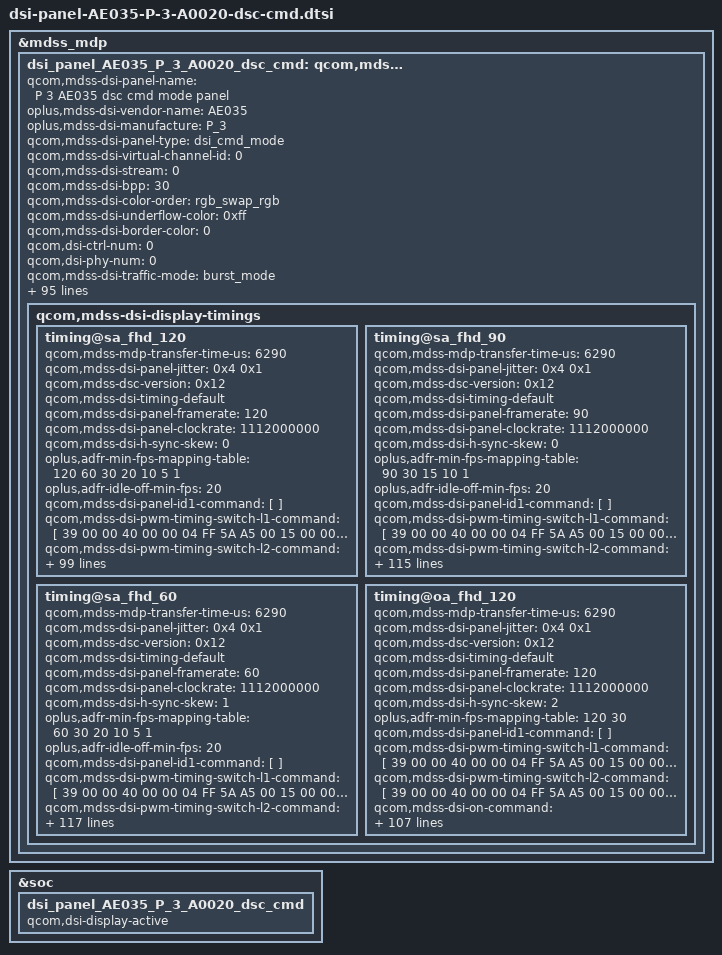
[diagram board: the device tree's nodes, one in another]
&mdss_mdp {
	dsi_panel_AE035_P_3_A0020_dsc_cmd: qcom,mdss_dsi_panel_AE035_P_3_A0020_dsc_cmd {
		qcom,mdss-dsi-panel-name = "P 3 AE035 dsc cmd mode panel";
		oplus,mdss-dsi-vendor-name = "AE035";
		oplus,mdss-dsi-manufacture = "P_3";
		qcom,mdss-dsi-panel-type = "dsi_cmd_mode";
		qcom,mdss-dsi-virtual-channel-id = <0>;
		qcom,mdss-dsi-stream = <0>;
		qcom,mdss-dsi-bpp = <30>;
		qcom,mdss-dsi-color-order = "rgb_swap_rgb";
		qcom,mdss-dsi-underflow-color = <0xff>;
		qcom,mdss-dsi-border-color = <0>;
		qcom,dsi-ctrl-num = <0>;
		qcom,dsi-phy-num = <0>;
		qcom,mdss-dsi-traffic-mode = "burst_mode";
		qcom,mdss-dsi-lane-map = "lane_map_0123";
		qcom,mdss-dsi-bllp-eof-power-mode;
		qcom,mdss-dsi-bllp-power-mode;
		qcom,mdss-dsi-lane-0-state;
		qcom,mdss-dsi-lane-1-state;
		qcom,mdss-dsi-lane-2-state;
		qcom,mdss-dsi-lane-3-state;
		qcom,mdss-dsi-dma-trigger = "trigger_sw";
		qcom,mdss-dsi-dma-schedule-line = <1>;
		qcom,mdss-dsi-dma-schedule-window = <10>;
		qcom,mdss-dsi-mdp-trigger = "none";
		qcom,mdss-dsi-reset-sequence = <1 2>, <0 5>, <1 25>;
		qcom,mdss-dsi-te-pin-select = <1>;
		qcom,mdss-dsi-te-dcs-command = <1>;
		qcom,mdss-pan-physical-width-dimension = <71>;
		qcom,mdss-pan-physical-height-dimension = <157>;
		qcom,mdss-dsi-init-delay-us = <1000>;
		qcom,mdss-dsi-te-check-enable;
		qcom,mdss-dsi-te-using-te-pin;
		//qcom,mdss-dsi-lp11-init;
		qcom,mdss-dsi-wr-mem-start = <0x2c>;
		qcom,mdss-dsi-wr-mem-continue = <0x3c>;
		qcom,mdss-dsi-panel-jitter = <0x4 0x1>;
		qcom,mdss-bl-high2bit;
		/* HDR Setting */
		qcom,mdss-dsi-panel-hdr-enabled;
		qcom,mdss-dsi-panel-hdr-color-primaries = <15635 16450 34000 16000 13250 34500 7500 3000>;
		qcom,mdss-dsi-panel-peak-brightness = <5400000>;
		qcom,mdss-dsi-panel-average-brightness = <2000000>;
		qcom,mdss-dsi-panel-blackness-level = <4000>;

		qcom,esd-check-enabled;
		oplus,esd-check-flag-enabled;
		qcom,mdss-dsi-panel-status-check-mode = "reg_read";
		qcom,mdss-dsi-panel-status-command = [
				06 00 00 00 00 00 01 0A
			];
		qcom,mdss-dsi-panel-status-command-state = "dsi_lp_mode";
		qcom,mdss-dsi-panel-status-value = <0x9C>;
		qcom,mdss-dsi-panel-status-read-length = <1>;

		qcom,mdss-dsi-display-timings {
			timing@sa_fhd_120 {
				#include "dsi-panel-AE035-P-3-A0020-dsc-cmd-common.dtsi"
				qcom,mdss-mdp-transfer-time-us = <6290>;
				qcom,mdss-dsi-panel-jitter = <0x4 0x1>;
				qcom,mdss-dsc-version = <0x12>;
				qcom,mdss-dsi-timing-default;
				qcom,mdss-dsi-panel-framerate = <120>;
				qcom,mdss-dsi-panel-clockrate = <1112000000>;

				/* standard adfr */
				qcom,mdss-dsi-h-sync-skew = <0>;
				oplus,adfr-min-fps-mapping-table = <120 60 30 20 10 5 1>;
				oplus,adfr-idle-off-min-fps = <20>;

				// oplus,ofp-need-to-sync-data-in-aod-unlocking;
				// oplus,ofp-aod-off-insert-black-frame = <1>;
				// oplus,ofp-aod-off-black-frame-total-time = <42>;
				// oplus,ofp-need-to-separate-backlight;
				// oplus,ofp-backlight-on-period = <1>;

				qcom,mdss-dsi-panel-id1-command = [

				];

				qcom,mdss-dsi-pwm-timing-switch-l1-command = [
						39 00 00 40 00 00 04 FF 5A A5 00
						15 00 00 40 00 00 02 60 00
						39 00 00 40 00 00 04 FF 5A A5 2D
						39 00 00 40 00 00 03 83 00 00
						15 00 00 40 00 00 02 F2 00
						39 00 00 00 00 00 04 FF 5A A5 00
				];

				qcom,mdss-dsi-pwm-timing-switch-l2-command = [
                                                39 00 00 40 00 00 04 FF 5A A5 00
                                                15 00 00 40 00 00 02 60 01
                                                39 00 00 40 00 00 04 FF 5A A5 2D
                                                39 00 00 40 00 00 03 84 00 00
                                                15 00 00 40 00 00 02 F2 00
                                                39 00 00 00 00 00 04 FF 5A A5 00
                                ];

				qcom,mdss-dsi-on-command = [
						39 00 00 40 00 00 04 FF 5A A5 08
						15 00 00 40 00 00 02 C8 62 // Sleep out don't reload
							/* PPS setting */
						39 00 00 40 00 00 04 FF 5A A5 07
						15 00 00 40 00 00 02 8A 01 // PPS Enable
						39 00 00 40 00 00 03 8B 11 E0 // PPS Table
						39 00 00 40 00 00 64 81 00 00 00 00 00 12 00
											00 AB 30 80 0A DC 04 F0
											00 14 02 78 02 78 02 00
											02 57 00 20 01 F8 00 08
											00 0D 05 7A 04 4F 18 00
											10 E0 07 10 20 00 06 0F
											0F 33 0E 1C 2A 38 46 54
											62 69 70 77 79 7B 7D 7E
											02 02 22 00 2A 40 2A BE
											3A FC 3A FA 3A F8 3B 38
											3B 78 3B B6 4B B6 4B F4
											4B F4 6C 34 84 74 00 00
											00 00 00 00
						39 00 00 40 00 00 04 FF 5A A5 21
						15 00 00 40 00 00 02 A4 18 // Flash reload enable
						/* ODC Compensation */
						39 00 00 40 00 00 04 FF 5A A5 49
						39 00 00 40 00 00 11 81 10 00 F3 01 3B 02 45 02 45 02 A9 03 8D 05 DD 06
						15 00 00 40 00 00 02 E0 01
						39 00 00 40 00 00 04 FF 5A A5 5A
						39 00 00 40 00 00 04 80 00 00 00
						39 00 00 40 00 00 04 81 19 25 1B
						39 00 00 40 00 00 04 82 10 20 14
						39 00 00 40 00 00 04 83 03 12 03
						39 00 00 40 00 00 04 84 01 0A 04
						39 00 00 40 00 00 04 85 01 0A 00
						39 00 00 40 00 00 04 86 02 22 12
						39 00 00 40 00 00 04 87 02 1C 0A
						39 00 00 40 00 00 04 88 02 16 08
						39 00 00 40 00 00 04 89 00 0A 08
						39 00 00 40 00 00 04 8A 01 24 20
						39 00 00 40 00 00 04 8B 01 1D 11
						39 00 00 40 00 00 04 8C 00 15 10
						39 00 00 40 00 00 04 8D 00 0E 0C
						39 00 00 40 00 00 04 8E 00 07 09
						39 00 00 40 00 00 04 8F 00 25 28
						39 00 00 40 00 00 04 90 02 1C 16
						39 00 00 40 00 00 04 91 02 12 14
						39 00 00 40 00 00 04 92 01 08 12
						39 00 00 40 00 00 04 93 01 06 0F
						39 00 00 40 00 00 04 94 00 03 02
						39 00 00 40 00 00 04 95 02 28 26
						39 00 00 40 00 00 04 96 02 22 24
						39 00 00 40 00 00 04 97 03 15 1E
						39 00 00 40 00 00 04 98 01 12 18
						39 00 00 40 00 00 04 99 01 07 16
						39 00 00 40 00 00 04 9A 01 05 0A
						39 00 00 40 00 00 04 9B 01 03 06
						39 00 00 40 00 00 04 A4 FA 01 FA
						39 00 00 40 00 00 04 A5 F9 02 FB
						39 00 00 40 00 00 04 A6 FB 01 FA
						39 00 00 40 00 00 04 A7 FC 02 FD
						39 00 00 40 00 00 04 A8 FA 01 FA
						39 00 00 40 00 00 04 A9 F8 00 FA
						39 00 00 40 00 00 04 AA 0C 0D 0F
						39 00 00 40 00 00 04 AB 07 05 06
						39 00 00 40 00 00 04 AC 06 04 05
						39 00 00 40 00 00 04 AD 03 02 03
						39 00 00 40 00 00 04 B3 22 28 26
						39 00 00 40 00 00 04 B4 16 1A 18
						39 00 00 40 00 00 04 B5 12 16 14
						39 00 00 40 00 00 04 B6 07 0D 0F
						39 00 00 40 00 00 04 B7 02 03 04
						39 00 00 40 00 00 04 B8 00 01 01
						39 00 00 40 00 00 04 B9 23 2A 27
						39 00 00 40 00 00 04 BA 19 1D 1B
						39 00 00 40 00 00 04 BB 14 1A 16
						39 00 00 40 00 00 04 BC 0C 10 0F
						39 00 00 40 00 00 04 BD 06 0B 0A
						39 00 00 40 00 00 04 BE 03 04 03
						39 00 00 40 00 00 04 BF 02 03 02
						39 00 00 40 00 00 04 C8 01 03 02
						39 00 00 40 00 00 04 C9 01 06 06
						39 00 00 40 00 00 04 CB 05 0B 09
						39 00 00 40 00 00 04 CC 01 02 01
						39 00 00 40 00 00 04 CD 00 01 01
						39 00 00 40 00 00 04 D7 1D 23 21
						39 00 00 40 00 00 04 D8 1A 1D 1A
						39 00 00 40 00 00 04 D9 14 18 16
						39 00 00 40 00 00 04 DA 03 07 0A
						39 00 00 40 00 00 04 DB 03 04 06
						39 00 00 40 00 00 04 DC 00 01 01
						39 00 00 40 00 00 04 DD 20 26 24
						39 00 00 40 00 00 04 DE 20 23 22
						39 00 00 40 00 00 04 DF 1A 1D 1C
						39 00 00 40 00 00 04 E0 12 14 16
						39 00 00 40 00 00 04 E1 09 0C 0D
						39 00 00 40 00 00 04 E2 02 03 05
						39 00 00 40 00 00 04 E3 01 02 03
						39 00 00 40 00 00 04 FF 5A A5 5B
						39 00 00 40 00 00 04 81 03 0A 09
						39 00 00 40 00 00 04 82 00 00 00
						39 00 00 40 00 00 04 83 05 0B 09
						39 00 00 40 00 00 04 8F 1E 24 22
						39 00 00 40 00 00 04 90 12 16 18
						39 00 00 40 00 00 04 91 0D 10 14
						39 00 00 40 00 00 04 92 06 09 12
						39 00 00 40 00 00 04 93 04 06 0C
						39 00 00 40 00 00 04 94 00 01 01
						39 00 00 40 00 00 04 95 20 26 24
						39 00 00 40 00 00 04 96 12 14 2F
						39 00 00 40 00 00 04 97 10 12 20
						39 00 00 40 00 00 04 98 0A 0C 1A
						39 00 00 40 00 00 04 99 06 08 13
						39 00 00 40 00 00 04 9A 04 04 08
						39 00 00 40 00 00 04 9B 03 03 06
						39 00 00 40 00 00 04 A5 03 09 07
						39 00 00 40 00 00 04 A6 00 00 00
						39 00 00 40 00 00 04 A7 05 0A 08
						39 00 00 40 00 00 04 B3 1E 24 22
						39 00 00 40 00 00 04 B4 12 16 18
						39 00 00 40 00 00 04 B5 0D 11 14
						39 00 00 40 00 00 04 B6 06 0A 10
						39 00 00 40 00 00 04 B7 04 07 0A
						39 00 00 40 00 00 04 B8 00 01 01
						39 00 00 40 00 00 04 B9 20 26 24
						39 00 00 40 00 00 04 BA 12 15 20
						39 00 00 40 00 00 04 BB 10 13 18
						39 00 00 40 00 00 04 BC 0A 0D 12
						39 00 00 40 00 00 04 BD 06 08 0A
						39 00 00 40 00 00 04 BE 02 05 08
						39 00 00 40 00 00 04 BF 02 03 06
						39 00 00 40 00 00 04 C9 04 06 05
						39 00 00 40 00 00 04 D4 08 0A 13
						39 00 00 40 00 00 04 D5 06 06 0D
						39 00 00 40 00 00 04 D6 02 02 07
						39 00 00 40 00 00 04 D7 15 1A 1A
						39 00 00 40 00 00 04 D8 12 13 18
						39 00 00 40 00 00 04 D9 0F 11 17
						39 00 00 40 00 00 04 DA 09 0B 10
						39 00 00 40 00 00 04 DB 02 03 08
						39 00 00 40 00 00 04 DC 00 01 01
						39 00 00 40 00 00 04 DD 2F 25 23
						39 00 00 40 00 00 04 DE 13 14 16
						39 00 00 40 00 00 04 DF 12 13 1E
						39 00 00 40 00 00 04 E0 10 12 16
						39 00 00 40 00 00 04 E1 0B 0E 11
						39 00 00 40 00 00 04 E2 03 04 07
						39 00 00 40 00 00 04 E3 02 03 05
						39 00 00 40 00 00 04 FF 5A A5 5C
						39 00 00 40 00 00 04 81 03 06 07
						39 00 00 40 00 00 04 8F 1B 22 20
						39 00 00 40 00 00 04 90 14 17 13
						39 00 00 40 00 00 04 91 0B 10 12
						39 00 00 40 00 00 04 92 03 06 0D
						39 00 00 40 00 00 04 93 02 03 06
						39 00 00 40 00 00 04 94 00 01 01
						39 00 00 40 00 00 04 95 1E 24 22
						39 00 00 40 00 00 04 96 11 13 1C
						39 00 00 40 00 00 04 97 10 12 16
						39 00 00 40 00 00 04 98 07 0A 13
						39 00 00 40 00 00 04 99 05 08 0A
						39 00 00 40 00 00 04 9A 01 02 04
						39 00 00 40 00 00 04 9B 00 01 03
						39 00 00 40 00 00 04 AE 16 19 16
						39 00 00 40 00 00 04 B3 1A 20 1E
						39 00 00 40 00 00 04 B4 12 14 12
						39 00 00 40 00 00 04 B5 10 12 13
						39 00 00 40 00 00 04 B6 06 08 0A
						39 00 00 40 00 00 04 B7 03 04 06
						39 00 00 40 00 00 04 B8 00 01 01
						39 00 00 40 00 00 04 B9 14 1A 18
						39 00 00 40 00 00 04 BA 12 14 14
						39 00 00 40 00 00 04 BB 10 12 13
						39 00 00 40 00 00 04 BC 08 0D 11
						39 00 00 40 00 00 04 BD 03 04 0B
						39 00 00 40 00 00 04 BE 02 02 04
						39 00 00 00 00 00 04 BF 02 03 03
						/* Crosstalk Compensation */
						39 00 00 40 00 00 04 FF 5A A5 31
						15 00 00 00 01 00 02 D0 81
						39 00 00 40 00 00 13 80 F0 99 62 25 02 FE DB 9E 67 E0 1A 17 16 00 00 E3 C8 C4
						39 00 00 40 00 00 13 81 F0 9C 65 25 02 FE DB 9B 64 E0 09 08 05 00 00 FD F4 EC
						39 00 00 40 00 00 13 82 F0 81 53 1F 02 FE E1 AD 7F E0 07 06 05 00 00 FD FC FB
						39 00 00 40 00 00 13 83 F0 70 48 1B 02 FE E5 B8 90 E0 07 06 05 00 00 FD FC FB
						39 00 00 40 00 00 13 84 F0 94 60 23 02 FE DD A0 6C E0 06 05 04 00 00 FB FA F9
						39 00 00 40 00 00 13 85 F0 7C 50 1E 02 FE E2 B0 84 E0 06 05 04 00 00 FB FA F9
						39 00 00 40 00 00 13 86 F0 99 62 25 02 FE DB 9E 67 E0 1A 17 16 00 00 E3 C8 C4
						39 00 00 40 00 00 13 87 F0 9C 65 25 02 FE DB 9B 64 E0 09 08 05 00 00 FD F4 EC
						39 00 00 40 00 00 13 88 F0 81 53 1F 02 FE E1 AD 7F E0 07 06 05 00 00 FD FC FB
						39 00 00 40 00 00 13 89 F0 70 48 1B 02 FE E5 B8 90 E0 07 06 05 00 00 FD FC FB
						39 00 00 40 00 00 13 8A F0 94 60 23 02 FE DD A0 6C E0 06 05 04 00 00 FB FA F9
						39 00 00 00 01 00 13 8B F0 7C 50 1E 02 FE E2 B0 84 E0 06 05 04 00 00 FB FA F9
						15 00 00 40 00 00 02 D0 80
						39 00 00 40 00 00 04 FF 5A A5 31
						15 00 00 40 00 00 02 9F 06
						15 00 00 40 00 00 02 A3 18
						15 00 00 40 00 00 02 A5 10
						39 00 00 40 00 00 19 8C 14 12 0E 0C 06 00 00 00 00 00 00 00 00 00 00 00 00 00 00 00 00 00 00 00
						39 00 00 40 00 00 1A 8D 06 05 05 04 04 00 00 00 00 00 00 00 00 00 00 00 00 00 00 00 00 00 00 00 80
						39 00 00 40 00 00 0B 90 01 02 04 05 09 01 02 04 05 09
						39 00 00 40 00 00 07 91 04 44 55 01 01 03
						39 00 00 40 00 00 07 92 04 44 55 01 01 03
						39 00 00 40 00 00 07 93 04 44 55 01 01 03
						39 00 00 40 00 00 09 8F 40 40 40 40 40 40 40 40
						15 00 00 40 00 00 02 A6 00
						15 00 00 40 00 00 02 A7 10
						15 00 00 40 00 00 02 A8 00
						15 00 00 40 00 00 02 A9 10
						15 00 00 40 00 00 02 AA 00
						15 00 00 40 00 00 02 AB 10
						15 00 00 40 00 00 02 A0 A3
						39 00 00 40 00 00 04 FF 5A A5 07
						15 00 00 40 00 00 02 E5 05
						39 00 00 40 00 00 07 E0 00 F0 06 DD 07 FF
						39 00 00 40 00 00 04 FF 5A A5 2B
						39 00 00 40 00 00 05 AA 30 F7 00 00
						39 00 00 40 00 00 05 AD 30 F9 00 00
						39 00 00 40 00 00 05 B0 30 FA 00 00
						39 00 00 40 00 00 05 B3 30 FC 00 00
						39 00 00 40 00 00 05 C4 0F 04 FB F1
						39 00 00 40 00 00 05 C5 3F DE E4 E4
						39 00 00 40 00 00 05 C7 3F F8 FD F5
						39 00 00 40 00 00 05 C8 3F E2 E9 E9
						39 00 00 40 00 00 05 CA 0F 02 FA F3
						39 00 00 40 00 00 05 CB 3F ED EF ED
						39 00 00 40 00 00 05 CD 03 02 00 FB
						39 00 00 40 00 00 05 DF 0F 04 F1 F6
						39 00 00 40 00 00 05 E0 3F D2 EB EE
						39 00 00 40 00 00 05 E2 3F F5 F0 F8
						39 00 00 40 00 00 05 E3 3F E2 EE E2
						39 00 00 40 00 00 05 E6 3F FE F3 F4
						39 00 00 40 00 00 05 E9 3F FD F7 F5
						39 00 00 40 00 00 05 EC 3F FD FA F7
						39 00 00 00 00 00 04 FF 5A A5 00
						/* Gamma Correction */
						39 00 00 40 00 00 04 FF 5A A5 2F
						15 00 00 40 00 00 02 99 80
						39 00 00 40 00 00 04 FF 5A A5 1F
						15 00 00 40 00 00 02 B2 00
						39 00 00 40 00 00 04 FF 5A A5 6E
						39 00 00 40 00 00 05 B8 00 5A 00 66
						39 00 00 40 00 00 05 B9 00 65 00 71
						39 00 00 40 00 00 05 BA 00 40 00 6F
						39 00 00 40 00 00 05 BB 00 6A 00 5B
						39 00 00 40 00 00 05 BC 00 62 00 65
						39 00 00 40 00 00 05 BD 00 62 00 5B
						39 00 00 40 00 00 05 BE 00 5A 00 58
						39 00 00 40 00 00 05 BF 00 5A 00 56
						39 00 00 40 00 00 05 C0 00 7D 00 7B
						39 00 00 40 00 00 05 C1 00 76 00 75
						39 00 00 40 00 00 05 C2 00 40 00 6F
						39 00 00 40 00 00 05 C3 00 65 00 54
						39 00 00 40 00 00 05 C4 00 50 00 4C
						39 00 00 40 00 00 05 C5 00 46 00 3C
						39 00 00 40 00 00 05 C6 00 38 00 35
						39 00 00 40 00 00 05 C7 00 32 00 2A
						39 00 00 40 00 00 05 C8 00 44 00 4E
						39 00 00 40 00 00 05 C9 00 50 00 52
						39 00 00 40 00 00 05 CA 00 40 00 4F
						39 00 00 40 00 00 05 CB 00 4F 00 42
						39 00 00 40 00 00 05 CC 00 41 00 41
						39 00 00 40 00 00 05 CD 00 3F 00 3E
						39 00 00 40 00 00 05 CE 00 3E 00 3D
						39 00 00 40 00 00 05 CF 00 3C 00 37
						39 00 00 40 00 00 05 D0 00 57 00 4D
						39 00 00 40 00 00 05 D1 00 4B 00 49
						39 00 00 40 00 00 05 D2 00 40 00 41
						39 00 00 40 00 00 05 D3 00 3F 00 34
						39 00 00 40 00 00 05 D4 00 32 00 2F
						39 00 00 40 00 00 05 D5 00 2B 00 2A
						39 00 00 40 00 00 05 D6 00 29 00 28
						39 00 00 40 00 00 05 D7 00 25 00 20
						39 00 00 40 00 00 04 FF 5A A5 24
						15 00 00 40 00 00 02 A1 01
						15 00 00 40 00 00 02 A2 E0
						15 00 00 40 00 00 02 A3 00
						39 00 00 40 00 00 0D A4 44 44 42 27 71 11 06 33 35 55 55 22
						39 00 00 40 00 00 1B D0 10 ED 0F FE 0D BB 0B 1A 07 52 04 8B 04 8A 04 76 03 E6 02 CB 01 E1 00 01 00 00
						39 00 00 40 00 00 04 FF 5A A5 1F
						15 00 00 40 00 00 02 B2 00
						39 00 00 40 00 00 04 FF 5A A5 6B
						39 00 00 40 00 00 05 95 74 88 4C 86
						39 00 00 40 00 00 05 96 11 A7 4D 71
						39 00 00 40 00 00 05 97 32 9E 4F B0
						39 00 00 40 00 00 05 98 10 C7 4B 38
						39 00 00 40 00 00 05 99 51 B9 4C 62
						39 00 00 40 00 00 05 9A BA DF 4F E9
						39 00 00 40 00 00 05 9B F8 2C 48 E0
						39 00 00 40 00 00 05 9C DA 29 46 B2
						39 00 00 40 00 00 05 9D 75 13 42 63
						39 00 00 40 00 00 05 9E BF 60 43 58
						39 00 00 40 00 00 05 9F 6A 82 46 1C
						39 00 00 40 00 00 05 A0 9D E8 4D 7E
						39 00 00 40 00 00 05 B9 74 88 4C 86
						39 00 00 40 00 00 05 BA 11 A7 4D 71
						39 00 00 40 00 00 05 BB 32 9E 4F B0
						39 00 00 40 00 00 05 BC 10 C7 4B 38
						39 00 00 40 00 00 05 BD 51 B9 4C 62
						39 00 00 40 00 00 05 BE BA DF 4F E9
						39 00 00 40 00 00 05 BF F8 2C 48 E0
						39 00 00 40 00 00 05 C0 DA 29 46 B2
						39 00 00 40 00 00 05 C1 75 13 42 63
						39 00 00 40 00 00 05 C2 BF 60 43 58
						39 00 00 40 00 00 05 C3 6A 82 46 1C
						39 00 00 40 00 00 05 C4 9D E8 4D 7E
						39 00 00 40 00 00 04 FF 5A A5 6C
						39 00 00 40 00 00 05 89 44 DF 41 F4
						39 00 00 40 00 00 05 8A 44 24 46 44
						39 00 00 40 00 00 05 8B 44 83 43 64
						39 00 00 40 00 00 05 8C 62 B7 44 69
						39 00 00 40 00 00 05 8D 76 B8 4B 77
						39 00 00 40 00 00 05 8E 48 AD 4E B7
						39 00 00 40 00 00 05 8F 32 03 43 3F
						39 00 00 40 00 00 05 90 33 73 42 30
						39 00 00 40 00 00 05 91 33 00 40 22
						39 00 00 40 00 00 05 92 DF 60 42 69
						39 00 00 40 00 00 05 93 6D 81 45 1D
						39 00 00 40 00 00 05 94 78 D7 4B 6A
						39 00 00 40 00 00 05 AD 44 DF 41 F4
						39 00 00 40 00 00 05 AE 44 24 46 44
						39 00 00 40 00 00 05 AF 44 83 43 64
						39 00 00 40 00 00 05 B0 62 B7 44 69
						39 00 00 40 00 00 05 B1 76 B8 4B 77
						39 00 00 40 00 00 05 B2 48 AD 4E B7
						39 00 00 40 00 00 05 B3 32 03 43 3F
						39 00 00 40 00 00 05 B4 33 73 42 30
						39 00 00 40 00 00 05 B5 33 00 40 22
						39 00 00 40 00 00 05 B6 DF 60 42 69
						39 00 00 40 00 00 05 B7 6D 81 45 1D
						39 00 00 40 00 00 05 B8 78 D7 4B 6A
						39 00 00 40 00 00 04 FF 5A A5 2F
						15 00 00 40 00 00 02 99 00
						39 00 00 40 00 00 04 FF 5A A5 00
						/*crosstalk*/
						39 00 00 40 00 00 04 FF 5A A5 28
						39 00 00 40 00 00 05 CA 0F 02 FA F3
						39 00 00 40 00 00 04 FF 5A A5 06
						15 00 00 40 00 00 02 98 04
						/* decreasing step */
						39 00 00 40 00 00 04 FF 5A A5 2D
						15 00 00 40 00 00 02 97 03
						15 00 00 40 00 00 02 B1 03
						39 00 00 40 00 00 03 98 03 00
						39 00 00 40 00 00 03 99 05 00
						39 00 00 40 00 00 03 9A 0B 00
						39 00 00 40 00 00 03 9B 17 00
						39 00 00 40 00 00 03 A0 00 00
						39 00 00 40 00 00 03 A1 01 02
						15 00 00 40 00 00 02 B2 02
						15 00 00 40 00 00 02 B3 04
						15 00 00 40 00 00 02 B4 08
						15 00 00 40 00 00 02 B5 11
						39 00 00 40 00 00 03 BA 00 00
						39 00 00 40 00 00 03 BB 01 02
						39 00 00 40 00 00 04 FF 5A A5 01
						15 00 00 40 00 00 02 FB 08
						39 00 00 40 00 00 04 FF 5A A5 00
						15 00 00 40 00 00 02 5E 01
						15 00 00 40 00 00 02 60 00
						15 00 00 40 00 00 02 61 07
						15 00 00 40 00 00 02 35 00
						15 00 00 40 00 00 02 53 20
						39 00 00 40 00 00 04 FF 5A A5 00
						15 00 00 40 00 00 02 60 00
						39 00 00 40 00 00 04 FF 5A A5 53
						39 00 00 40 00 00 03 85 CC E1
						39 00 00 40 00 00 04 FF 5A A5 2D
						39 00 00 40 00 00 03 83 00 00
						15 00 00 40 00 00 02 F2 00
						39 00 00 00 00 00 04 FF 5A A5 00
						15 00 00 00 78 00 02 11 00 // Sleep OUT
						15 00 00 00 00 00 02 29 00 // Display ON
				];

				qcom,mdss-dsi-adfr-auto-on-command = [
					/* SDC Auto On */
				];
				qcom,mdss-dsi-adfr-auto-off-command = [
					/* SDC Auto Off */
				];

				qcom,mdss-dsi-post-on-backlight = [

				];

				qcom,mdss-dsi-panel-read-register-open-command = [
				];
				qcom,mdss-dsi-panel-read-register-close-command = [
				];

				qcom,mdss-dsi-temperature-compensation-command = [
				];
				qcom,mdss-dsi-read-compensation-reg1-command = [
				];

				qcom,mdss-dsi-pwm-switch-mode0-command = [
					39 00 00 40 00 00 04 FF 5A A5 00
					15 00 00 40 00 00 02 60 00
					39 00 00 00 00 00 04 FF 5A A5 00
				];

				qcom,mdss-dsi-pwm-switch-mode1-command = [
                                        39 00 00 40 00 00 04 FF 5A A5 00
                                        15 00 00 40 00 00 02 60 01
                                        39 00 00 00 00 00 04 FF 5A A5 00
                                ];

				qcom,mdss-dsi-adfr-min-fps-0-command = [
					//120Hz
					39 00 00 40 00 00 04 FF 5A A5 2D
					39 00 00 40 00 00 03 83 00 00
					39 00 00 40 00 00 03 84 00 00
					39 00 00 00 00 00 04 FF 5A A5 00
				];
				qcom,mdss-dsi-adfr-min-fps-1-command = [
					//60Hz
					39 00 00 40 00 00 04 FF 5A A5 2D
					39 00 00 40 00 00 03 83 01 00
					39 00 00 40 00 00 03 84 01 00
					39 00 00 00 00 00 04 FF 5A A5 00
				];
				qcom,mdss-dsi-adfr-min-fps-2-command = [
					//30Hz
					39 00 00 40 00 00 04 FF 5A A5 2D
					39 00 00 40 00 00 03 83 03 00
					39 00 00 40 00 00 03 84 03 00
					39 00 00 00 00 00 04 FF 5A A5 00
				];
				qcom,mdss-dsi-adfr-min-fps-3-command = [
					//20Hz
					39 00 00 40 00 00 04 FF 5A A5 2D
					39 00 00 40 00 00 03 83 05 00
					39 00 00 40 00 00 03 84 05 00
					39 00 00 00 00 00 04 FF 5A A5 00
				];
				qcom,mdss-dsi-adfr-min-fps-4-command = [
					//10Hz
					39 00 00 40 00 00 04 FF 5A A5 2D
					39 00 00 40 00 00 03 83 0B 00
					39 00 00 40 00 00 03 84 0B 00
					39 00 00 00 00 00 04 FF 5A A5 00
				];
				qcom,mdss-dsi-adfr-min-fps-5-command = [
					//5Hz
					39 00 00 40 00 00 04 FF 5A A5 2D
					39 00 00 40 00 00 03 83 17 00
					39 00 00 40 00 00 03 84 17 00
					39 00 00 00 00 00 04 FF 5A A5 00
				];
				qcom,mdss-dsi-adfr-min-fps-6-command = [
					//1Hz
					39 00 00 40 00 00 04 FF 5A A5 2D
					39 00 00 40 00 00 03 83 77 00
					39 00 00 40 00 00 03 84 77 00
					39 00 00 00 00 00 04 FF 5A A5 00
				];


				qcom,mdss-dsi-on-command-state = "dsi_lp_mode";
				qcom,mdss-dsi-on-high-fre-command-state = "dsi_lp_mode";
				qcom,mdss-dsi-nolp-hpwm-command-state = "dsi_lp_sync1_mode";
				qcom,mdss-dsi-panel-read-register-open-state = "dsi_lp_mode";
				qcom,mdss-dsi-panel-read-register-close-state = "dsi_lp_mode";
				qcom,mdss-dsi-reset-scanline-command-state = "dsi_hs_mode";
				qcom,mdss-dsi-recovery-scanline-command-state = "dsi_hs_mode";

				qcom,mdss-dsi-adfr-auto-on-command-state ="dsi_hs_mode";
				qcom,mdss-dsi-adfr-auto-off-command-state ="dsi_hs_mode";
				qcom,mdss-dsi-temperature-compensation-command-state = "dsi_hs_mode";
				qcom,mdss-dsi-read-compensation-reg1-command-state = "dsi_hs_mode";
				qcom,mdss-dsi-osc-track-on-command-state = "dsi_hs_mode";
				qcom,mdss-dsi-osc-track-off-command-state = "dsi_hs_mode";
				qcom,mdss-dsi-hbm-max-command-state = "dsi_hs_mode";
				qcom,mdss-dsi-hbm-exit-max-command-state = "dsi_hs_mode";

				qcom,mdss-dsi-pwm-timing-switch-l1-command-state = "dsi_hs_mode";
				qcom,mdss-dsi-pwm-timing-switch-l2-command-state = "dsi_hs_mode";
				qcom,mdss-dsi-pwm-switch-mode0-command-state = "dsi_hs_mode";
				qcom,mdss-dsi-pwm-switch-mode1-command-state = "dsi_hs_mode";

				qcom,mdss-dsi-adfr-min-fps-0-command-state = "dsi_hs_mode";
				qcom,mdss-dsi-adfr-min-fps-1-command-state = "dsi_hs_mode";
				qcom,mdss-dsi-adfr-min-fps-2-command-state = "dsi_hs_mode";
				qcom,mdss-dsi-adfr-min-fps-3-command-state = "dsi_hs_mode";
				qcom,mdss-dsi-adfr-min-fps-4-command-state = "dsi_hs_mode";
				qcom,mdss-dsi-adfr-min-fps-5-command-state = "dsi_hs_mode";
				qcom,mdss-dsi-adfr-min-fps-6-command-state = "dsi_hs_mode";

				qcom,lm-split = <632 632>;
				qcom,compression-mode = "dsc";
				qcom,mdss-dsc-encoders = <2>;
				qcom,mdss-dsc-slice-height = <20>;
				qcom,mdss-dsc-slice-width = <632>;
				qcom,mdss-dsc-slice-per-pkt = <2>;
				qcom,mdss-dsc-bit-per-component = <10>;
				qcom,mdss-dsc-bit-per-pixel = <8>;
				qcom,mdss-dsc-block-prediction-enable;
				qcom,mdss-dsi-panel-id1-command-state = "dsi_lp_mode";
			};
			timing@sa_fhd_90 {
				#include "dsi-panel-AE035-P-3-A0020-dsc-cmd-common.dtsi"
				qcom,mdss-mdp-transfer-time-us = <6290>;
				qcom,mdss-dsi-panel-jitter = <0x4 0x1>;
				qcom,mdss-dsc-version = <0x12>;
				qcom,mdss-dsi-timing-default;
				qcom,mdss-dsi-panel-framerate = <90>;
				qcom,mdss-dsi-panel-clockrate = <1112000000>;

				/* standard adfr */
				qcom,mdss-dsi-h-sync-skew = <0>;
				oplus,adfr-min-fps-mapping-table = <90 30 15 10 1>;
				oplus,adfr-idle-off-min-fps = <20>;

				// oplus,ofp-need-to-sync-data-in-aod-unlocking;
				// oplus,ofp-aod-off-insert-black-frame = <1>;
				// oplus,ofp-aod-off-black-frame-total-time = <42>;
				// oplus,ofp-need-to-separate-backlight;
				// oplus,ofp-backlight-on-period = <1>;

				qcom,mdss-dsi-panel-id1-command = [

				];

                                qcom,mdss-dsi-pwm-timing-switch-l1-command = [
                                                39 00 00 40 00 00 04 FF 5A A5 00
                                                15 00 00 40 00 00 02 60 02
                                                39 00 00 40 00 00 04 FF 5A A5 2D
                                                39 00 00 40 00 00 03 85 00 00
                                                15 00 00 40 00 00 02 F2 00
                                                39 00 00 00 00 00 04 FF 5A A5 00
                                ];

                                qcom,mdss-dsi-pwm-timing-switch-l2-command = [
                                                39 00 00 40 00 00 04 FF 5A A5 00
                                                15 00 00 40 00 00 02 60 03
                                                39 00 00 40 00 00 04 FF 5A A5 2D
                                                39 00 00 40 00 00 03 86 00 00
                                                15 00 00 40 00 00 02 F2 00
                                                39 00 00 00 00 00 04 FF 5A A5 00
                                ];

				qcom,mdss-dsi-on-command = [
						39 00 00 40 00 00 04 FF 5A A5 08
						15 00 00 40 00 00 02 C8 62 // Sleep out don't reload
							/* PPS setting */
						39 00 00 40 00 00 04 FF 5A A5 07
						15 00 00 40 00 00 02 8A 01 // PPS Enable
						39 00 00 40 00 00 03 8B 11 E0 // PPS Table
						39 00 00 40 00 00 64 81 00 00 00 00 00 12 00
											00 AB 30 80 0A DC 04 F0
											00 14 02 78 02 78 02 00
											02 57 00 20 01 F8 00 08
											00 0D 05 7A 04 4F 18 00
											10 E0 07 10 20 00 06 0F
											0F 33 0E 1C 2A 38 46 54
											62 69 70 77 79 7B 7D 7E
											02 02 22 00 2A 40 2A BE
											3A FC 3A FA 3A F8 3B 38
											3B 78 3B B6 4B B6 4B F4
											4B F4 6C 34 84 74 00 00
											00 00 00 00
						39 00 00 40 00 00 04 FF 5A A5 21
						15 00 00 40 00 00 02 A4 18 // Flash reload enable
						/* ODC Compensation */
						39 00 00 40 00 00 04 FF 5A A5 49
						39 00 00 40 00 00 11 81 10 00 F3 01 3B 02 45 02 45 02 A9 03 8D 05 DD 06
						15 00 00 40 00 00 02 E0 01
						39 00 00 40 00 00 04 FF 5A A5 5A
						39 00 00 40 00 00 04 80 00 00 00
						39 00 00 40 00 00 04 81 19 25 1B
						39 00 00 40 00 00 04 82 10 20 14
						39 00 00 40 00 00 04 83 03 12 03
						39 00 00 40 00 00 04 84 01 0A 04
						39 00 00 40 00 00 04 85 01 0A 00
						39 00 00 40 00 00 04 86 02 22 12
						39 00 00 40 00 00 04 87 02 1C 0A
						39 00 00 40 00 00 04 88 02 16 08
						39 00 00 40 00 00 04 89 00 0A 08
						39 00 00 40 00 00 04 8A 01 24 20
						39 00 00 40 00 00 04 8B 01 1D 11
						39 00 00 40 00 00 04 8C 00 15 10
						39 00 00 40 00 00 04 8D 00 0E 0C
						39 00 00 40 00 00 04 8E 00 07 09
						39 00 00 40 00 00 04 8F 00 25 28
						39 00 00 40 00 00 04 90 02 1C 16
						39 00 00 40 00 00 04 91 02 12 14
						39 00 00 40 00 00 04 92 01 08 12
						39 00 00 40 00 00 04 93 01 06 0F
						39 00 00 40 00 00 04 94 00 03 02
						39 00 00 40 00 00 04 95 02 28 26
						39 00 00 40 00 00 04 96 02 22 24
						39 00 00 40 00 00 04 97 03 15 1E
						39 00 00 40 00 00 04 98 01 12 18
						39 00 00 40 00 00 04 99 01 07 16
						39 00 00 40 00 00 04 9A 01 05 0A
						39 00 00 40 00 00 04 9B 01 03 06
						39 00 00 40 00 00 04 A4 FA 01 FA
						39 00 00 40 00 00 04 A5 F9 02 FB
						39 00 00 40 00 00 04 A6 FB 01 FA
						39 00 00 40 00 00 04 A7 FC 02 FD
						39 00 00 40 00 00 04 A8 FA 01 FA
						39 00 00 40 00 00 04 A9 F8 00 FA
						39 00 00 40 00 00 04 AA 0C 0D 0F
						39 00 00 40 00 00 04 AB 07 05 06
						39 00 00 40 00 00 04 AC 06 04 05
						39 00 00 40 00 00 04 AD 03 02 03
						39 00 00 40 00 00 04 B3 22 28 26
						39 00 00 40 00 00 04 B4 16 1A 18
						39 00 00 40 00 00 04 B5 12 16 14
						39 00 00 40 00 00 04 B6 07 0D 0F
						39 00 00 40 00 00 04 B7 02 03 04
						39 00 00 40 00 00 04 B8 00 01 01
						39 00 00 40 00 00 04 B9 23 2A 27
						39 00 00 40 00 00 04 BA 19 1D 1B
						39 00 00 40 00 00 04 BB 14 1A 16
						39 00 00 40 00 00 04 BC 0C 10 0F
						39 00 00 40 00 00 04 BD 06 0B 0A
						39 00 00 40 00 00 04 BE 03 04 03
						39 00 00 40 00 00 04 BF 02 03 02
						39 00 00 40 00 00 04 C8 01 03 02
						39 00 00 40 00 00 04 C9 01 06 06
						39 00 00 40 00 00 04 CB 05 0B 09
						39 00 00 40 00 00 04 CC 01 02 01
						39 00 00 40 00 00 04 CD 00 01 01
						39 00 00 40 00 00 04 D7 1D 23 21
						39 00 00 40 00 00 04 D8 1A 1D 1A
						39 00 00 40 00 00 04 D9 14 18 16
						39 00 00 40 00 00 04 DA 03 07 0A
						39 00 00 40 00 00 04 DB 03 04 06
						39 00 00 40 00 00 04 DC 00 01 01
						39 00 00 40 00 00 04 DD 20 26 24
						39 00 00 40 00 00 04 DE 20 23 22
						39 00 00 40 00 00 04 DF 1A 1D 1C
						39 00 00 40 00 00 04 E0 12 14 16
						39 00 00 40 00 00 04 E1 09 0C 0D
						39 00 00 40 00 00 04 E2 02 03 05
						39 00 00 40 00 00 04 E3 01 02 03
						39 00 00 40 00 00 04 FF 5A A5 5B
						39 00 00 40 00 00 04 81 03 0A 09
						39 00 00 40 00 00 04 82 00 00 00
						39 00 00 40 00 00 04 83 05 0B 09
						39 00 00 40 00 00 04 8F 1E 24 22
						39 00 00 40 00 00 04 90 12 16 18
						39 00 00 40 00 00 04 91 0D 10 14
						39 00 00 40 00 00 04 92 06 09 12
						39 00 00 40 00 00 04 93 04 06 0C
						39 00 00 40 00 00 04 94 00 01 01
						39 00 00 40 00 00 04 95 20 26 24
						39 00 00 40 00 00 04 96 12 14 2F
						39 00 00 40 00 00 04 97 10 12 20
						39 00 00 40 00 00 04 98 0A 0C 1A
						39 00 00 40 00 00 04 99 06 08 13
						39 00 00 40 00 00 04 9A 04 04 08
						39 00 00 40 00 00 04 9B 03 03 06
						39 00 00 40 00 00 04 A5 03 09 07
						39 00 00 40 00 00 04 A6 00 00 00
						39 00 00 40 00 00 04 A7 05 0A 08
						39 00 00 40 00 00 04 B3 1E 24 22
						39 00 00 40 00 00 04 B4 12 16 18
						39 00 00 40 00 00 04 B5 0D 11 14
						39 00 00 40 00 00 04 B6 06 0A 10
						39 00 00 40 00 00 04 B7 04 07 0A
						39 00 00 40 00 00 04 B8 00 01 01
						39 00 00 40 00 00 04 B9 20 26 24
						39 00 00 40 00 00 04 BA 12 15 20
						39 00 00 40 00 00 04 BB 10 13 18
						39 00 00 40 00 00 04 BC 0A 0D 12
						39 00 00 40 00 00 04 BD 06 08 0A
						39 00 00 40 00 00 04 BE 02 05 08
						39 00 00 40 00 00 04 BF 02 03 06
						39 00 00 40 00 00 04 C9 04 06 05
						39 00 00 40 00 00 04 D4 08 0A 13
						39 00 00 40 00 00 04 D5 06 06 0D
						39 00 00 40 00 00 04 D6 02 02 07
						39 00 00 40 00 00 04 D7 15 1A 1A
						39 00 00 40 00 00 04 D8 12 13 18
						39 00 00 40 00 00 04 D9 0F 11 17
						39 00 00 40 00 00 04 DA 09 0B 10
						39 00 00 40 00 00 04 DB 02 03 08
						39 00 00 40 00 00 04 DC 00 01 01
						39 00 00 40 00 00 04 DD 2F 25 23
						39 00 00 40 00 00 04 DE 13 14 16
						39 00 00 40 00 00 04 DF 12 13 1E
						39 00 00 40 00 00 04 E0 10 12 16
						39 00 00 40 00 00 04 E1 0B 0E 11
						39 00 00 40 00 00 04 E2 03 04 07
						39 00 00 40 00 00 04 E3 02 03 05
						39 00 00 40 00 00 04 FF 5A A5 5C
						39 00 00 40 00 00 04 81 03 06 07
						39 00 00 40 00 00 04 8F 1B 22 20
						39 00 00 40 00 00 04 90 14 17 13
						39 00 00 40 00 00 04 91 0B 10 12
						39 00 00 40 00 00 04 92 03 06 0D
						39 00 00 40 00 00 04 93 02 03 06
						39 00 00 40 00 00 04 94 00 01 01
						39 00 00 40 00 00 04 95 1E 24 22
						39 00 00 40 00 00 04 96 11 13 1C
						39 00 00 40 00 00 04 97 10 12 16
						39 00 00 40 00 00 04 98 07 0A 13
						39 00 00 40 00 00 04 99 05 08 0A
						39 00 00 40 00 00 04 9A 01 02 04
						39 00 00 40 00 00 04 9B 00 01 03
						39 00 00 40 00 00 04 AE 16 19 16
						39 00 00 40 00 00 04 B3 1A 20 1E
						39 00 00 40 00 00 04 B4 12 14 12
						39 00 00 40 00 00 04 B5 10 12 13
						39 00 00 40 00 00 04 B6 06 08 0A
						39 00 00 40 00 00 04 B7 03 04 06
						39 00 00 40 00 00 04 B8 00 01 01
						39 00 00 40 00 00 04 B9 14 1A 18
						39 00 00 40 00 00 04 BA 12 14 14
						39 00 00 40 00 00 04 BB 10 12 13
						39 00 00 40 00 00 04 BC 08 0D 11
						39 00 00 40 00 00 04 BD 03 04 0B
						39 00 00 40 00 00 04 BE 02 02 04
						39 00 00 00 00 00 04 BF 02 03 03
						/* Crosstalk Compensation */
						39 00 00 40 00 00 04 FF 5A A5 31
						15 00 00 00 01 00 02 D0 81
						39 00 00 40 00 00 13 80 F0 99 62 25 02 FE DB 9E 67 E0 1A 17 16 00 00 E3 C8 C4
						39 00 00 40 00 00 13 81 F0 9C 65 25 02 FE DB 9B 64 E0 09 08 05 00 00 FD F4 EC
						39 00 00 40 00 00 13 82 F0 81 53 1F 02 FE E1 AD 7F E0 07 06 05 00 00 FD FC FB
						39 00 00 40 00 00 13 83 F0 70 48 1B 02 FE E5 B8 90 E0 07 06 05 00 00 FD FC FB
						39 00 00 40 00 00 13 84 F0 94 60 23 02 FE DD A0 6C E0 06 05 04 00 00 FB FA F9
						39 00 00 40 00 00 13 85 F0 7C 50 1E 02 FE E2 B0 84 E0 06 05 04 00 00 FB FA F9
						39 00 00 40 00 00 13 86 F0 99 62 25 02 FE DB 9E 67 E0 1A 17 16 00 00 E3 C8 C4
						39 00 00 40 00 00 13 87 F0 9C 65 25 02 FE DB 9B 64 E0 09 08 05 00 00 FD F4 EC
						39 00 00 40 00 00 13 88 F0 81 53 1F 02 FE E1 AD 7F E0 07 06 05 00 00 FD FC FB
						39 00 00 40 00 00 13 89 F0 70 48 1B 02 FE E5 B8 90 E0 07 06 05 00 00 FD FC FB
						39 00 00 40 00 00 13 8A F0 94 60 23 02 FE DD A0 6C E0 06 05 04 00 00 FB FA F9
						39 00 00 00 01 00 13 8B F0 7C 50 1E 02 FE E2 B0 84 E0 06 05 04 00 00 FB FA F9
						15 00 00 40 00 00 02 D0 80
						39 00 00 40 00 00 04 FF 5A A5 31
						15 00 00 40 00 00 02 9F 06
						15 00 00 40 00 00 02 A3 18
						15 00 00 40 00 00 02 A5 10
						39 00 00 40 00 00 19 8C 14 12 0E 0C 06 00 00 00 00 00 00 00 00 00 00 00 00 00 00 00 00 00 00 00
						39 00 00 40 00 00 1A 8D 06 05 05 04 04 00 00 00 00 00 00 00 00 00 00 00 00 00 00 00 00 00 00 00 80
						39 00 00 40 00 00 0B 90 01 02 04 05 09 01 02 04 05 09
						39 00 00 40 00 00 07 91 04 44 55 01 01 03
						39 00 00 40 00 00 07 92 04 44 55 01 01 03
						39 00 00 40 00 00 07 93 04 44 55 01 01 03
						39 00 00 40 00 00 09 8F 40 40 40 40 40 40 40 40
						15 00 00 40 00 00 02 A6 00
						15 00 00 40 00 00 02 A7 10
						15 00 00 40 00 00 02 A8 00
						15 00 00 40 00 00 02 A9 10
						15 00 00 40 00 00 02 AA 00
						15 00 00 40 00 00 02 AB 10
						15 00 00 40 00 00 02 A0 A3
						39 00 00 40 00 00 04 FF 5A A5 07
						15 00 00 40 00 00 02 E5 05
						39 00 00 40 00 00 07 E0 00 F0 06 DD 07 FF
						39 00 00 40 00 00 04 FF 5A A5 2B
						39 00 00 40 00 00 05 AA 30 F7 00 00
						39 00 00 40 00 00 05 AD 30 F9 00 00
						39 00 00 40 00 00 05 B0 30 FA 00 00
						39 00 00 40 00 00 05 B3 30 FC 00 00
						39 00 00 40 00 00 05 C4 0F 04 FB F1
						39 00 00 40 00 00 05 C5 3F DE E4 E4
						39 00 00 40 00 00 05 C7 3F F8 FD F5
						39 00 00 40 00 00 05 C8 3F E2 E9 E9
						39 00 00 40 00 00 05 CA 0F 02 FA F3
						39 00 00 40 00 00 05 CB 3F ED EF ED
						39 00 00 40 00 00 05 CD 03 02 00 FB
						39 00 00 40 00 00 05 DF 0F 04 F1 F6
						39 00 00 40 00 00 05 E0 3F D2 EB EE
						39 00 00 40 00 00 05 E2 3F F5 F0 F8
						39 00 00 40 00 00 05 E3 3F E2 EE E2
						39 00 00 40 00 00 05 E6 3F FE F3 F4
						39 00 00 40 00 00 05 E9 3F FD F7 F5
						39 00 00 40 00 00 05 EC 3F FD FA F7
						39 00 00 00 00 00 04 FF 5A A5 00
						/* Gamma Correction */
                                                39 00 00 40 00 00 04 FF 5A A5 2F
                                                15 00 00 40 00 00 02 99 80
                                                39 00 00 40 00 00 04 FF 5A A5 1F
                                                15 00 00 40 00 00 02 B2 00
                                                39 00 00 40 00 00 04 FF 5A A5 6E
                                                39 00 00 40 00 00 05 B8 00 5A 00 66
                                                39 00 00 40 00 00 05 B9 00 65 00 71
                                                39 00 00 40 00 00 05 BA 00 40 00 6F
                                                39 00 00 40 00 00 05 BB 00 6A 00 5B
                                                39 00 00 40 00 00 05 BC 00 62 00 65
                                                39 00 00 40 00 00 05 BD 00 62 00 5B
                                                39 00 00 40 00 00 05 BE 00 5A 00 58
                                                39 00 00 40 00 00 05 BF 00 5A 00 56
                                                39 00 00 40 00 00 05 C0 00 7D 00 7B
                                                39 00 00 40 00 00 05 C1 00 76 00 75
                                                39 00 00 40 00 00 05 C2 00 40 00 6F
                                                39 00 00 40 00 00 05 C3 00 65 00 54
                                                39 00 00 40 00 00 05 C4 00 50 00 4C
                                                39 00 00 40 00 00 05 C5 00 46 00 3C
                                                39 00 00 40 00 00 05 C6 00 38 00 35
                                                39 00 00 40 00 00 05 C7 00 32 00 2A
                                                39 00 00 40 00 00 05 C8 00 44 00 4E
                                                39 00 00 40 00 00 05 C9 00 50 00 52
                                                39 00 00 40 00 00 05 CA 00 40 00 4F
                                                39 00 00 40 00 00 05 CB 00 4F 00 42
                                                39 00 00 40 00 00 05 CC 00 41 00 41
                                                39 00 00 40 00 00 05 CD 00 3F 00 3E
                                                39 00 00 40 00 00 05 CE 00 3E 00 3D
                                                39 00 00 40 00 00 05 CF 00 3C 00 37
                                                39 00 00 40 00 00 05 D0 00 57 00 4D
                                                39 00 00 40 00 00 05 D1 00 4B 00 49
                                                39 00 00 40 00 00 05 D2 00 40 00 41
                                                39 00 00 40 00 00 05 D3 00 3F 00 34
                                                39 00 00 40 00 00 05 D4 00 32 00 2F
                                                39 00 00 40 00 00 05 D5 00 2B 00 2A
                                                39 00 00 40 00 00 05 D6 00 29 00 28
                                                39 00 00 40 00 00 05 D7 00 25 00 20
                                                39 00 00 40 00 00 04 FF 5A A5 24
                                                15 00 00 40 00 00 02 A1 01
                                                15 00 00 40 00 00 02 A2 E0
                                                15 00 00 40 00 00 02 A3 00
                                                39 00 00 40 00 00 0D A4 44 44 42 27 71 11 06 33 35 55 55 22
                                                39 00 00 40 00 00 1B D0 10 ED 0F FE 0D BB 0B 1A 07 52 04 8B 04 8A 04 76 03 E6 02 CB 01 E1 00 01 00 00
                                                39 00 00 40 00 00 04 FF 5A A5 1F
                                                15 00 00 40 00 00 02 B2 00
                                                39 00 00 40 00 00 04 FF 5A A5 6B
                                                39 00 00 40 00 00 05 95 74 88 4C 86
                                                39 00 00 40 00 00 05 96 11 A7 4D 71
                                                39 00 00 40 00 00 05 97 32 9E 4F B0
                                                39 00 00 40 00 00 05 98 10 C7 4B 38
                                                39 00 00 40 00 00 05 99 51 B9 4C 62
                                                39 00 00 40 00 00 05 9A BA DF 4F E9
                                                39 00 00 40 00 00 05 9B F8 2C 48 E0
                                                39 00 00 40 00 00 05 9C DA 29 46 B2
                                                39 00 00 40 00 00 05 9D 75 13 42 63
                                                39 00 00 40 00 00 05 9E BF 60 43 58
						39 00 00 40 00 00 05 9F 6A 82 46 1C
                                                39 00 00 40 00 00 05 A0 9D E8 4D 7E
                                                39 00 00 40 00 00 05 B9 74 88 4C 86
                                                39 00 00 40 00 00 05 BA 11 A7 4D 71
                                                39 00 00 40 00 00 05 BB 32 9E 4F B0
                                                39 00 00 40 00 00 05 BC 10 C7 4B 38
                                                39 00 00 40 00 00 05 BD 51 B9 4C 62
                                                39 00 00 40 00 00 05 BE BA DF 4F E9
                                                39 00 00 40 00 00 05 BF F8 2C 48 E0
                                                39 00 00 40 00 00 05 C0 DA 29 46 B2
                                                39 00 00 40 00 00 05 C1 75 13 42 63
                                                39 00 00 40 00 00 05 C2 BF 60 43 58
                                                39 00 00 40 00 00 05 C3 6A 82 46 1C
                                                39 00 00 40 00 00 05 C4 9D E8 4D 7E
                                                39 00 00 40 00 00 04 FF 5A A5 6C
                                                39 00 00 40 00 00 05 89 44 DF 41 F4
                                                39 00 00 40 00 00 05 8A 44 24 46 44
                                                39 00 00 40 00 00 05 8B 44 83 43 64
                                                39 00 00 40 00 00 05 8C 62 B7 44 69
                                                39 00 00 40 00 00 05 8D 76 B8 4B 77
                                                39 00 00 40 00 00 05 8E 48 AD 4E B7
                                                39 00 00 40 00 00 05 8F 32 03 43 3F
                                                39 00 00 40 00 00 05 90 33 73 42 30
                                                39 00 00 40 00 00 05 91 33 00 40 22
                                                39 00 00 40 00 00 05 92 DF 60 42 69
                                                39 00 00 40 00 00 05 93 6D 81 45 1D
                                                39 00 00 40 00 00 05 94 78 D7 4B 6A
                                                39 00 00 40 00 00 05 AD 44 DF 41 F4
                                                39 00 00 40 00 00 05 AE 44 24 46 44
                                                39 00 00 40 00 00 05 AF 44 83 43 64
                                                39 00 00 40 00 00 05 B0 62 B7 44 69
                                                39 00 00 40 00 00 05 B1 76 B8 4B 77
                                                39 00 00 40 00 00 05 B2 48 AD 4E B7
                                                39 00 00 40 00 00 05 B3 32 03 43 3F
                                                39 00 00 40 00 00 05 B4 33 73 42 30
                                                39 00 00 40 00 00 05 B5 33 00 40 22
                                                39 00 00 40 00 00 05 B6 DF 60 42 69
                                                39 00 00 40 00 00 05 B7 6D 81 45 1D
                                                39 00 00 40 00 00 05 B8 78 D7 4B 6A
                                                39 00 00 40 00 00 04 FF 5A A5 2F
                                                15 00 00 40 00 00 02 99 00
                                                39 00 00 40 00 00 04 FF 5A A5 00
						39 00 00 40 00 00 04 FF 5A A5 28
                                                39 00 00 40 00 00 05 CA 0F 02 FA F3
                                                39 00 00 40 00 00 04 FF 5A A5 06
                                                15 00 00 40 00 00 02 98 04
						/* decreasing step */
						39 00 00 40 00 00 04 FF 5A A5 2D
						15 00 00 40 00 00 02 97 03
						15 00 00 40 00 00 02 B1 03
						39 00 00 40 00 00 03 98 03 00
						39 00 00 40 00 00 03 99 05 00
						39 00 00 40 00 00 03 9A 0B 00
						39 00 00 40 00 00 03 9B 17 00
						39 00 00 40 00 00 03 A0 00 00
						39 00 00 40 00 00 03 A1 01 02
						15 00 00 40 00 00 02 B2 02
						15 00 00 40 00 00 02 B3 04
						15 00 00 40 00 00 02 B4 08
						15 00 00 40 00 00 02 B5 11
						39 00 00 40 00 00 03 BA 00 00
						39 00 00 40 00 00 03 BB 01 02
						39 00 00 40 00 00 04 FF 5A A5 01
						15 00 00 40 00 00 02 FB 08
						39 00 00 40 00 00 04 FF 5A A5 00
						15 00 00 40 00 00 02 5E 01
						15 00 00 40 00 00 02 60 00
						15 00 00 40 00 00 02 61 07
						15 00 00 40 00 00 02 35 00
						15 00 00 40 00 00 02 53 20
						39 00 00 40 00 00 04 FF 5A A5 00
						15 00 00 40 00 00 02 60 02
						39 00 00 40 00 00 04 FF 5A A5 53
						39 00 00 40 00 00 03 85 CC E1
						39 00 00 40 00 00 04 FF 5A A5 2D
						39 00 00 40 00 00 03 83 00 00
						15 00 00 40 00 00 02 F2 00
						39 00 00 00 00 00 04 FF 5A A5 00
						15 00 00 00 78 00 02 11 00 // Sleep OUT
						15 00 00 00 00 00 02 29 00 // Display ON
				];

				qcom,mdss-dsi-adfr-auto-on-command = [
					/* SDC Auto On */
				];
				qcom,mdss-dsi-adfr-auto-off-command = [
					/* SDC Auto Off */
				];

				qcom,mdss-dsi-post-on-backlight = [

				];

				qcom,mdss-dsi-panel-read-register-open-command = [
				];
				qcom,mdss-dsi-panel-read-register-close-command = [
				];

				qcom,mdss-dsi-temperature-compensation-command = [
				];
				qcom,mdss-dsi-read-compensation-reg1-command = [
				];

				qcom,mdss-dsi-pwm-switch-mode0-command = [
                                        39 00 00 40 00 00 04 FF 5A A5 00
                                        15 00 00 40 00 00 02 60 02
                                        39 00 00 00 00 00 04 FF 5A A5 00
                                ];

                                qcom,mdss-dsi-pwm-switch-mode1-command = [
                                        39 00 00 40 00 00 04 FF 5A A5 00
                                        15 00 00 40 00 00 02 60 03
                                        39 00 00 00 00 00 04 FF 5A A5 00
                                ];

				qcom,mdss-dsi-adfr-min-fps-0-command = [
					//90Hz
					39 00 00 40 00 00 04 FF 5A A5 2D
					39 00 00 40 00 00 03 85 00 00
					39 00 00 40 00 00 03 86 00 00
					39 00 00 00 00 00 04 FF 5A A5 00
				];
				qcom,mdss-dsi-adfr-min-fps-1-command = [
					//30Hz
					39 00 00 40 00 00 04 FF 5A A5 2D
					39 00 00 40 00 00 03 85 02 00
					39 00 00 40 00 00 03 86 02 00
					39 00 00 00 00 00 04 FF 5A A5 00
				];
				qcom,mdss-dsi-adfr-min-fps-2-command = [
					//15Hz
					39 00 00 40 00 00 04 FF 5A A5 2D
					39 00 00 40 00 00 03 85 05 00
					39 00 00 40 00 00 03 86 05 00
					39 00 00 00 00 00 04 FF 5A A5 00
				];
				qcom,mdss-dsi-adfr-min-fps-3-command = [
					//10Hz
					39 00 00 40 00 00 04 FF 5A A5 2D
					39 00 00 40 00 00 03 85 08 00
					39 00 00 40 00 00 03 86 08 00
					39 00 00 00 00 00 04 FF 5A A5 00
				];
				qcom,mdss-dsi-adfr-min-fps-4-command = [
					//1Hz
					39 00 00 40 00 00 04 FF 5A A5 2D
					39 00 00 40 00 00 03 85 59 00
					39 00 00 40 00 00 03 86 59 00
					39 00 00 00 00 00 04 FF 5A A5 00
				];

				qcom,mdss-dsi-timing-switch-command-state = "dsi_hs_sync1_mode";
				qcom,mdss-dsi-timing-switch-high-fre-command-state = "dsi_hs_mode";
				qcom,mdss-dsi-on-command-state = "dsi_lp_mode";
				qcom,mdss-dsi-on-high-fre-command-state = "dsi_lp_mode";
				qcom,mdss-dsi-nolp-hpwm-command-state = "dsi_lp_sync1_mode";
				qcom,mdss-dsi-panel-read-register-open-state = "dsi_lp_mode";
				qcom,mdss-dsi-panel-read-register-close-state = "dsi_lp_mode";
				qcom,mdss-dsi-reset-scanline-command-state = "dsi_hs_mode";
				qcom,mdss-dsi-recovery-scanline-command-state = "dsi_hs_mode";

				qcom,mdss-dsi-adfr-auto-on-command-state ="dsi_hs_mode";
				qcom,mdss-dsi-adfr-auto-off-command-state ="dsi_hs_mode";
				qcom,mdss-dsi-temperature-compensation-command-state = "dsi_hs_mode";
				qcom,mdss-dsi-read-compensation-reg1-command-state = "dsi_hs_mode";
				qcom,mdss-dsi-lpwm-pulse-command-state = "dsi_hs_mode";
				qcom,mdss-dsi-hpwm-pulse-command-state = "dsi_hs_mode";
				qcom,mdss-dsi-pwm-switch-high-command-state = "dsi_hs_sync1_mode";
				qcom,mdss-dsi-pwm-switch-low-command-state = "dsi_hs_sync1_mode";
				qcom,mdss-dsi-power-on-pwm-switch-onepulse-command-state = "dsi_hs_mode";
				qcom,mdss-dsi-pwm-switch-1ptodc-command-state = "dsi_hs_sync1_mode";
				qcom,mdss-dsi-pwm-switch-dcto1p-command-state = "dsi_hs_sync1_mode";
				qcom,mdss-dsi-pwm-switch-1ptohp-command-state = "dsi_hs_sync1_mode";
				qcom,mdss-dsi-pwm-switch-hpto1p-command-state = "dsi_hs_sync1_mode";
				qcom,mdss-dsi-timming-pwm-switch-onepulse-command-state = "dsi_hs_sync1_mode";
				qcom,mdss-dsi-osc-track-on-command-state = "dsi_hs_mode";
				qcom,mdss-dsi-osc-track-off-command-state = "dsi_hs_mode";
				qcom,mdss-dsi-hbm-max-command-state = "dsi_hs_mode";
				qcom,mdss-dsi-hbm-exit-max-command-state = "dsi_hs_mode";

				qcom,mdss-dsi-pwm-switch-1to3-command-state = "dsi_hs_mode";
				qcom,mdss-dsi-pwm-switch-3to1-command-state = "dsi_hs_mode";

				qcom,mdss-dsi-adfr-min-fps-0-command-state = "dsi_hs_mode";
				qcom,mdss-dsi-adfr-min-fps-1-command-state = "dsi_hs_mode";
				qcom,mdss-dsi-adfr-min-fps-2-command-state = "dsi_hs_mode";
				qcom,mdss-dsi-adfr-min-fps-3-command-state = "dsi_hs_mode";
				qcom,mdss-dsi-adfr-min-fps-4-command-state = "dsi_hs_mode";
				qcom,mdss-dsi-adfr-min-fps-5-command-state = "dsi_hs_mode";
				qcom,mdss-dsi-adfr-min-fps-6-command-state = "dsi_hs_mode";

				qcom,lm-split = <632 632>;
				qcom,compression-mode = "dsc";
				qcom,mdss-dsc-encoders = <2>;
				qcom,mdss-dsc-slice-height = <20>;
				qcom,mdss-dsc-slice-width = <632>;
				qcom,mdss-dsc-slice-per-pkt = <2>;
				qcom,mdss-dsc-bit-per-component = <10>;
				qcom,mdss-dsc-bit-per-pixel = <8>;
				qcom,mdss-dsc-block-prediction-enable;
				qcom,mdss-dsi-panel-id1-command-state = "dsi_lp_mode";
			};
			timing@sa_fhd_60 {
				#include "dsi-panel-AE035-P-3-A0020-dsc-cmd-common.dtsi"
				qcom,mdss-mdp-transfer-time-us = <6290>;
				qcom,mdss-dsi-panel-jitter = <0x4 0x1>;
				qcom,mdss-dsc-version = <0x12>;
				qcom,mdss-dsi-timing-default;
				qcom,mdss-dsi-panel-framerate = <60>;
				qcom,mdss-dsi-panel-clockrate = <1112000000>;

				/* standard adfr */
				qcom,mdss-dsi-h-sync-skew = <1>;
				oplus,adfr-min-fps-mapping-table = <60 30 20 10 5 1>;
				oplus,adfr-idle-off-min-fps = <20>;

				// oplus,ofp-need-to-sync-data-in-aod-unlocking;
				// oplus,ofp-aod-off-insert-black-frame = <1>;
				// oplus,ofp-aod-off-black-frame-total-time = <42>;
				// oplus,ofp-need-to-separate-backlight;
				// oplus,ofp-backlight-on-period = <1>;

				qcom,mdss-dsi-panel-id1-command = [

				];

                                qcom,mdss-dsi-pwm-timing-switch-l1-command = [
                                                39 00 00 40 00 00 04 FF 5A A5 00
                                                15 00 00 40 00 00 02 60 00
                                                39 00 00 40 00 00 04 FF 5A A5 2D
                                                39 00 00 40 00 00 03 83 01 00
                                                15 00 00 40 00 00 02 F2 01
                                                39 00 00 00 00 00 04 FF 5A A5 00
                                ];

                                qcom,mdss-dsi-pwm-timing-switch-l2-command = [
                                                39 00 00 40 00 00 04 FF 5A A5 00
                                                15 00 00 40 00 00 02 60 01
                                                39 00 00 40 00 00 04 FF 5A A5 2D
                                                39 00 00 40 00 00 03 84 01 00
                                                15 00 00 40 00 00 02 F2 01
                                                39 00 00 00 00 00 04 FF 5A A5 00
                                ];

				qcom,mdss-dsi-on-command = [
						39 00 00 40 00 00 04 FF 5A A5 08
						15 00 00 40 00 00 02 C8 62 // Sleep out don't reload
							/* PPS setting */
						39 00 00 40 00 00 04 FF 5A A5 07
						15 00 00 40 00 00 02 8A 01 // PPS Enable
						39 00 00 40 00 00 03 8B 11 E0 // PPS Table
						39 00 00 40 00 00 64 81 00 00 00 00 00 12 00
											00 AB 30 80 0A DC 04 F0
											00 14 02 78 02 78 02 00
											02 57 00 20 01 F8 00 08
											00 0D 05 7A 04 4F 18 00
											10 E0 07 10 20 00 06 0F
											0F 33 0E 1C 2A 38 46 54
											62 69 70 77 79 7B 7D 7E
											02 02 22 00 2A 40 2A BE
											3A FC 3A FA 3A F8 3B 38
											3B 78 3B B6 4B B6 4B F4
											4B F4 6C 34 84 74 00 00
											00 00 00 00
						39 00 00 40 00 00 04 FF 5A A5 21
						15 00 00 40 00 00 02 A4 18 // Flash reload enable
						/* ODC Compensation */
						39 00 00 40 00 00 04 FF 5A A5 49
						39 00 00 40 00 00 11 81 10 00 F3 01 3B 02 45 02 45 02 A9 03 8D 05 DD 06
						15 00 00 40 00 00 02 E0 01
						39 00 00 40 00 00 04 FF 5A A5 5A
						39 00 00 40 00 00 04 80 00 00 00
						39 00 00 40 00 00 04 81 19 25 1B
						39 00 00 40 00 00 04 82 10 20 14
						39 00 00 40 00 00 04 83 03 12 03
						39 00 00 40 00 00 04 84 01 0A 04
						39 00 00 40 00 00 04 85 01 0A 00
						39 00 00 40 00 00 04 86 02 22 12
						39 00 00 40 00 00 04 87 02 1C 0A
						39 00 00 40 00 00 04 88 02 16 08
						39 00 00 40 00 00 04 89 00 0A 08
						39 00 00 40 00 00 04 8A 01 24 20
						39 00 00 40 00 00 04 8B 01 1D 11
						39 00 00 40 00 00 04 8C 00 15 10
						39 00 00 40 00 00 04 8D 00 0E 0C
						39 00 00 40 00 00 04 8E 00 07 09
						39 00 00 40 00 00 04 8F 00 25 28
						39 00 00 40 00 00 04 90 02 1C 16
						39 00 00 40 00 00 04 91 02 12 14
						39 00 00 40 00 00 04 92 01 08 12
						39 00 00 40 00 00 04 93 01 06 0F
						39 00 00 40 00 00 04 94 00 03 02
						39 00 00 40 00 00 04 95 02 28 26
						39 00 00 40 00 00 04 96 02 22 24
						39 00 00 40 00 00 04 97 03 15 1E
						39 00 00 40 00 00 04 98 01 12 18
						39 00 00 40 00 00 04 99 01 07 16
						39 00 00 40 00 00 04 9A 01 05 0A
						39 00 00 40 00 00 04 9B 01 03 06
						39 00 00 40 00 00 04 A4 FA 01 FA
						39 00 00 40 00 00 04 A5 F9 02 FB
						39 00 00 40 00 00 04 A6 FB 01 FA
						39 00 00 40 00 00 04 A7 FC 02 FD
						39 00 00 40 00 00 04 A8 FA 01 FA
						39 00 00 40 00 00 04 A9 F8 00 FA
						39 00 00 40 00 00 04 AA 0C 0D 0F
						39 00 00 40 00 00 04 AB 07 05 06
						39 00 00 40 00 00 04 AC 06 04 05
						39 00 00 40 00 00 04 AD 03 02 03
						39 00 00 40 00 00 04 B3 22 28 26
						39 00 00 40 00 00 04 B4 16 1A 18
						39 00 00 40 00 00 04 B5 12 16 14
						39 00 00 40 00 00 04 B6 07 0D 0F
						39 00 00 40 00 00 04 B7 02 03 04
						39 00 00 40 00 00 04 B8 00 01 01
						39 00 00 40 00 00 04 B9 23 2A 27
						39 00 00 40 00 00 04 BA 19 1D 1B
						39 00 00 40 00 00 04 BB 14 1A 16
						39 00 00 40 00 00 04 BC 0C 10 0F
						39 00 00 40 00 00 04 BD 06 0B 0A
						39 00 00 40 00 00 04 BE 03 04 03
						39 00 00 40 00 00 04 BF 02 03 02
						39 00 00 40 00 00 04 C8 01 03 02
						39 00 00 40 00 00 04 C9 01 06 06
						39 00 00 40 00 00 04 CB 05 0B 09
						39 00 00 40 00 00 04 CC 01 02 01
						39 00 00 40 00 00 04 CD 00 01 01
						39 00 00 40 00 00 04 D7 1D 23 21
						39 00 00 40 00 00 04 D8 1A 1D 1A
						39 00 00 40 00 00 04 D9 14 18 16
						39 00 00 40 00 00 04 DA 03 07 0A
						39 00 00 40 00 00 04 DB 03 04 06
						39 00 00 40 00 00 04 DC 00 01 01
						39 00 00 40 00 00 04 DD 20 26 24
						39 00 00 40 00 00 04 DE 20 23 22
						39 00 00 40 00 00 04 DF 1A 1D 1C
						39 00 00 40 00 00 04 E0 12 14 16
						39 00 00 40 00 00 04 E1 09 0C 0D
						39 00 00 40 00 00 04 E2 02 03 05
						39 00 00 40 00 00 04 E3 01 02 03
						39 00 00 40 00 00 04 FF 5A A5 5B
						39 00 00 40 00 00 04 81 03 0A 09
						39 00 00 40 00 00 04 82 00 00 00
						39 00 00 40 00 00 04 83 05 0B 09
						39 00 00 40 00 00 04 8F 1E 24 22
						39 00 00 40 00 00 04 90 12 16 18
						39 00 00 40 00 00 04 91 0D 10 14
						39 00 00 40 00 00 04 92 06 09 12
						39 00 00 40 00 00 04 93 04 06 0C
						39 00 00 40 00 00 04 94 00 01 01
						39 00 00 40 00 00 04 95 20 26 24
						39 00 00 40 00 00 04 96 12 14 2F
						39 00 00 40 00 00 04 97 10 12 20
						39 00 00 40 00 00 04 98 0A 0C 1A
						39 00 00 40 00 00 04 99 06 08 13
						39 00 00 40 00 00 04 9A 04 04 08
						39 00 00 40 00 00 04 9B 03 03 06
						39 00 00 40 00 00 04 A5 03 09 07
						39 00 00 40 00 00 04 A6 00 00 00
						39 00 00 40 00 00 04 A7 05 0A 08
						39 00 00 40 00 00 04 B3 1E 24 22
						39 00 00 40 00 00 04 B4 12 16 18
						39 00 00 40 00 00 04 B5 0D 11 14
						39 00 00 40 00 00 04 B6 06 0A 10
						39 00 00 40 00 00 04 B7 04 07 0A
						39 00 00 40 00 00 04 B8 00 01 01
						39 00 00 40 00 00 04 B9 20 26 24
						39 00 00 40 00 00 04 BA 12 15 20
						39 00 00 40 00 00 04 BB 10 13 18
						39 00 00 40 00 00 04 BC 0A 0D 12
						39 00 00 40 00 00 04 BD 06 08 0A
						39 00 00 40 00 00 04 BE 02 05 08
						39 00 00 40 00 00 04 BF 02 03 06
						39 00 00 40 00 00 04 C9 04 06 05
						39 00 00 40 00 00 04 D4 08 0A 13
						39 00 00 40 00 00 04 D5 06 06 0D
						39 00 00 40 00 00 04 D6 02 02 07
						39 00 00 40 00 00 04 D7 15 1A 1A
						39 00 00 40 00 00 04 D8 12 13 18
						39 00 00 40 00 00 04 D9 0F 11 17
						39 00 00 40 00 00 04 DA 09 0B 10
						39 00 00 40 00 00 04 DB 02 03 08
						39 00 00 40 00 00 04 DC 00 01 01
						39 00 00 40 00 00 04 DD 2F 25 23
						39 00 00 40 00 00 04 DE 13 14 16
						39 00 00 40 00 00 04 DF 12 13 1E
						39 00 00 40 00 00 04 E0 10 12 16
						39 00 00 40 00 00 04 E1 0B 0E 11
						39 00 00 40 00 00 04 E2 03 04 07
						39 00 00 40 00 00 04 E3 02 03 05
						39 00 00 40 00 00 04 FF 5A A5 5C
						39 00 00 40 00 00 04 81 03 06 07
						39 00 00 40 00 00 04 8F 1B 22 20
						39 00 00 40 00 00 04 90 14 17 13
						39 00 00 40 00 00 04 91 0B 10 12
						39 00 00 40 00 00 04 92 03 06 0D
						39 00 00 40 00 00 04 93 02 03 06
						39 00 00 40 00 00 04 94 00 01 01
						39 00 00 40 00 00 04 95 1E 24 22
						39 00 00 40 00 00 04 96 11 13 1C
						39 00 00 40 00 00 04 97 10 12 16
						39 00 00 40 00 00 04 98 07 0A 13
						39 00 00 40 00 00 04 99 05 08 0A
						39 00 00 40 00 00 04 9A 01 02 04
						39 00 00 40 00 00 04 9B 00 01 03
						39 00 00 40 00 00 04 AE 16 19 16
						39 00 00 40 00 00 04 B3 1A 20 1E
						39 00 00 40 00 00 04 B4 12 14 12
						39 00 00 40 00 00 04 B5 10 12 13
						39 00 00 40 00 00 04 B6 06 08 0A
						39 00 00 40 00 00 04 B7 03 04 06
						39 00 00 40 00 00 04 B8 00 01 01
						39 00 00 40 00 00 04 B9 14 1A 18
						39 00 00 40 00 00 04 BA 12 14 14
						39 00 00 40 00 00 04 BB 10 12 13
						39 00 00 40 00 00 04 BC 08 0D 11
						39 00 00 40 00 00 04 BD 03 04 0B
						39 00 00 40 00 00 04 BE 02 02 04
						39 00 00 00 00 00 04 BF 02 03 03
						/* Crosstalk Compensation */
						39 00 00 40 00 00 04 FF 5A A5 31
						15 00 00 00 01 00 02 D0 81
						39 00 00 40 00 00 13 80 F0 99 62 25 02 FE DB 9E 67 E0 1A 17 16 00 00 E3 C8 C4
						39 00 00 40 00 00 13 81 F0 9C 65 25 02 FE DB 9B 64 E0 09 08 05 00 00 FD F4 EC
						39 00 00 40 00 00 13 82 F0 81 53 1F 02 FE E1 AD 7F E0 07 06 05 00 00 FD FC FB
						39 00 00 40 00 00 13 83 F0 70 48 1B 02 FE E5 B8 90 E0 07 06 05 00 00 FD FC FB
						39 00 00 40 00 00 13 84 F0 94 60 23 02 FE DD A0 6C E0 06 05 04 00 00 FB FA F9
						39 00 00 40 00 00 13 85 F0 7C 50 1E 02 FE E2 B0 84 E0 06 05 04 00 00 FB FA F9
						39 00 00 40 00 00 13 86 F0 99 62 25 02 FE DB 9E 67 E0 1A 17 16 00 00 E3 C8 C4
						39 00 00 40 00 00 13 87 F0 9C 65 25 02 FE DB 9B 64 E0 09 08 05 00 00 FD F4 EC
						39 00 00 40 00 00 13 88 F0 81 53 1F 02 FE E1 AD 7F E0 07 06 05 00 00 FD FC FB
						39 00 00 40 00 00 13 89 F0 70 48 1B 02 FE E5 B8 90 E0 07 06 05 00 00 FD FC FB
						39 00 00 40 00 00 13 8A F0 94 60 23 02 FE DD A0 6C E0 06 05 04 00 00 FB FA F9
						39 00 00 00 01 00 13 8B F0 7C 50 1E 02 FE E2 B0 84 E0 06 05 04 00 00 FB FA F9
						15 00 00 40 00 00 02 D0 80
						39 00 00 40 00 00 04 FF 5A A5 31
						15 00 00 40 00 00 02 9F 06
						15 00 00 40 00 00 02 A3 18
						15 00 00 40 00 00 02 A5 10
						39 00 00 40 00 00 19 8C 14 12 0E 0C 06 00 00 00 00 00 00 00 00 00 00 00 00 00 00 00 00 00 00 00
						39 00 00 40 00 00 1A 8D 06 05 05 04 04 00 00 00 00 00 00 00 00 00 00 00 00 00 00 00 00 00 00 00 80
						39 00 00 40 00 00 0B 90 01 02 04 05 09 01 02 04 05 09
						39 00 00 40 00 00 07 91 04 44 55 01 01 03
						39 00 00 40 00 00 07 92 04 44 55 01 01 03
						39 00 00 40 00 00 07 93 04 44 55 01 01 03
						39 00 00 40 00 00 09 8F 40 40 40 40 40 40 40 40
						15 00 00 40 00 00 02 A6 00
						15 00 00 40 00 00 02 A7 10
						15 00 00 40 00 00 02 A8 00
						15 00 00 40 00 00 02 A9 10
						15 00 00 40 00 00 02 AA 00
						15 00 00 40 00 00 02 AB 10
						15 00 00 40 00 00 02 A0 A3
						39 00 00 40 00 00 04 FF 5A A5 07
						15 00 00 40 00 00 02 E5 05
						39 00 00 40 00 00 07 E0 00 F0 06 DD 07 FF
						39 00 00 40 00 00 04 FF 5A A5 2B
						39 00 00 40 00 00 05 AA 30 F7 00 00
						39 00 00 40 00 00 05 AD 30 F9 00 00
						39 00 00 40 00 00 05 B0 30 FA 00 00
						39 00 00 40 00 00 05 B3 30 FC 00 00
						39 00 00 40 00 00 05 C4 0F 04 FB F1
						39 00 00 40 00 00 05 C5 3F DE E4 E4
						39 00 00 40 00 00 05 C7 3F F8 FD F5
						39 00 00 40 00 00 05 C8 3F E2 E9 E9
						39 00 00 40 00 00 05 CA 0F 02 FA F3
						39 00 00 40 00 00 05 CB 3F ED EF ED
						39 00 00 40 00 00 05 CD 03 02 00 FB
						39 00 00 40 00 00 05 DF 0F 04 F1 F6
						39 00 00 40 00 00 05 E0 3F D2 EB EE
						39 00 00 40 00 00 05 E2 3F F5 F0 F8
						39 00 00 40 00 00 05 E3 3F E2 EE E2
						39 00 00 40 00 00 05 E6 3F FE F3 F4
						39 00 00 40 00 00 05 E9 3F FD F7 F5
						39 00 00 40 00 00 05 EC 3F FD FA F7
						39 00 00 00 00 00 04 FF 5A A5 00
						/* Gamma Correction */
                                                39 00 00 40 00 00 04 FF 5A A5 2F
                                                15 00 00 40 00 00 02 99 80
                                                39 00 00 40 00 00 04 FF 5A A5 1F
                                                15 00 00 40 00 00 02 B2 00
                                                39 00 00 40 00 00 04 FF 5A A5 6E
                                                39 00 00 40 00 00 05 B8 00 5A 00 66
                                                39 00 00 40 00 00 05 B9 00 65 00 71
                                                39 00 00 40 00 00 05 BA 00 40 00 6F
                                                39 00 00 40 00 00 05 BB 00 6A 00 5B
                                                39 00 00 40 00 00 05 BC 00 62 00 65
                                                39 00 00 40 00 00 05 BD 00 62 00 5B
                                                39 00 00 40 00 00 05 BE 00 5A 00 58
                                                39 00 00 40 00 00 05 BF 00 5A 00 56
                                                39 00 00 40 00 00 05 C0 00 7D 00 7B
                                                39 00 00 40 00 00 05 C1 00 76 00 75
                                                39 00 00 40 00 00 05 C2 00 40 00 6F
                                                39 00 00 40 00 00 05 C3 00 65 00 54
                                                39 00 00 40 00 00 05 C4 00 50 00 4C
                                                39 00 00 40 00 00 05 C5 00 46 00 3C
                                                39 00 00 40 00 00 05 C6 00 38 00 35
                                                39 00 00 40 00 00 05 C7 00 32 00 2A
                                                39 00 00 40 00 00 05 C8 00 44 00 4E
                                                39 00 00 40 00 00 05 C9 00 50 00 52
                                                39 00 00 40 00 00 05 CA 00 40 00 4F
                                                39 00 00 40 00 00 05 CB 00 4F 00 42
                                                39 00 00 40 00 00 05 CC 00 41 00 41
                                                39 00 00 40 00 00 05 CD 00 3F 00 3E
                                                39 00 00 40 00 00 05 CE 00 3E 00 3D
                                                39 00 00 40 00 00 05 CF 00 3C 00 37
                                                39 00 00 40 00 00 05 D0 00 57 00 4D
                                                39 00 00 40 00 00 05 D1 00 4B 00 49
                                                39 00 00 40 00 00 05 D2 00 40 00 41
                                                39 00 00 40 00 00 05 D3 00 3F 00 34
                                                39 00 00 40 00 00 05 D4 00 32 00 2F
                                                39 00 00 40 00 00 05 D5 00 2B 00 2A
                                                39 00 00 40 00 00 05 D6 00 29 00 28
                                                39 00 00 40 00 00 05 D7 00 25 00 20
                                                39 00 00 40 00 00 04 FF 5A A5 24
                                                15 00 00 40 00 00 02 A1 01
                                                15 00 00 40 00 00 02 A2 E0
                                                15 00 00 40 00 00 02 A3 00
                                                39 00 00 40 00 00 0D A4 44 44 42 27 71 11 06 33 35 55 55 22
                                                39 00 00 40 00 00 1B D0 10 ED 0F FE 0D BB 0B 1A 07 52 04 8B 04 8A 04 76 03 E6 02 CB 01 E1 00 01 00 00
                                                39 00 00 40 00 00 04 FF 5A A5 1F
                                                15 00 00 40 00 00 02 B2 00
                                                39 00 00 40 00 00 04 FF 5A A5 6B
                                                39 00 00 40 00 00 05 95 74 88 4C 86
                                                39 00 00 40 00 00 05 96 11 A7 4D 71
                                                39 00 00 40 00 00 05 97 32 9E 4F B0
                                                39 00 00 40 00 00 05 98 10 C7 4B 38
                                                39 00 00 40 00 00 05 99 51 B9 4C 62
                                                39 00 00 40 00 00 05 9A BA DF 4F E9
                                                39 00 00 40 00 00 05 9B F8 2C 48 E0
                                                39 00 00 40 00 00 05 9C DA 29 46 B2
                                                39 00 00 40 00 00 05 9D 75 13 42 63
                                                39 00 00 40 00 00 05 9E BF 60 43 58
						39 00 00 40 00 00 05 9F 6A 82 46 1C
                                                39 00 00 40 00 00 05 A0 9D E8 4D 7E
                                                39 00 00 40 00 00 05 B9 74 88 4C 86
                                                39 00 00 40 00 00 05 BA 11 A7 4D 71
                                                39 00 00 40 00 00 05 BB 32 9E 4F B0
                                                39 00 00 40 00 00 05 BC 10 C7 4B 38
                                                39 00 00 40 00 00 05 BD 51 B9 4C 62
                                                39 00 00 40 00 00 05 BE BA DF 4F E9
                                                39 00 00 40 00 00 05 BF F8 2C 48 E0
                                                39 00 00 40 00 00 05 C0 DA 29 46 B2
                                                39 00 00 40 00 00 05 C1 75 13 42 63
                                                39 00 00 40 00 00 05 C2 BF 60 43 58
                                                39 00 00 40 00 00 05 C3 6A 82 46 1C
                                                39 00 00 40 00 00 05 C4 9D E8 4D 7E
                                                39 00 00 40 00 00 04 FF 5A A5 6C
                                                39 00 00 40 00 00 05 89 44 DF 41 F4
                                                39 00 00 40 00 00 05 8A 44 24 46 44
                                                39 00 00 40 00 00 05 8B 44 83 43 64
                                                39 00 00 40 00 00 05 8C 62 B7 44 69
                                                39 00 00 40 00 00 05 8D 76 B8 4B 77
                                                39 00 00 40 00 00 05 8E 48 AD 4E B7
                                                39 00 00 40 00 00 05 8F 32 03 43 3F
                                                39 00 00 40 00 00 05 90 33 73 42 30
                                                39 00 00 40 00 00 05 91 33 00 40 22
                                                39 00 00 40 00 00 05 92 DF 60 42 69
                                                39 00 00 40 00 00 05 93 6D 81 45 1D
                                                39 00 00 40 00 00 05 94 78 D7 4B 6A
                                                39 00 00 40 00 00 05 AD 44 DF 41 F4
                                                39 00 00 40 00 00 05 AE 44 24 46 44
                                                39 00 00 40 00 00 05 AF 44 83 43 64
                                                39 00 00 40 00 00 05 B0 62 B7 44 69
                                                39 00 00 40 00 00 05 B1 76 B8 4B 77
                                                39 00 00 40 00 00 05 B2 48 AD 4E B7
                                                39 00 00 40 00 00 05 B3 32 03 43 3F
                                                39 00 00 40 00 00 05 B4 33 73 42 30
                                                39 00 00 40 00 00 05 B5 33 00 40 22
                                                39 00 00 40 00 00 05 B6 DF 60 42 69
                                                39 00 00 40 00 00 05 B7 6D 81 45 1D
                                                39 00 00 40 00 00 05 B8 78 D7 4B 6A
                                                39 00 00 40 00 00 04 FF 5A A5 2F
                                                15 00 00 40 00 00 02 99 00
                                                39 00 00 40 00 00 04 FF 5A A5 00
						39 00 00 40 00 00 04 FF 5A A5 28
                                                39 00 00 40 00 00 05 CA 0F 02 FA F3
                                                39 00 00 40 00 00 04 FF 5A A5 06
                                                15 00 00 40 00 00 02 98 04
												/* decreasing step */
						39 00 00 40 00 00 04 FF 5A A5 2D
						15 00 00 40 00 00 02 97 03
						15 00 00 40 00 00 02 B1 03
						39 00 00 40 00 00 03 98 03 00
						39 00 00 40 00 00 03 99 05 00
						39 00 00 40 00 00 03 9A 0B 00
						39 00 00 40 00 00 03 9B 17 00
						39 00 00 40 00 00 03 A0 00 00
						39 00 00 40 00 00 03 A1 01 02
						15 00 00 40 00 00 02 B2 02
						15 00 00 40 00 00 02 B3 04
						15 00 00 40 00 00 02 B4 08
						15 00 00 40 00 00 02 B5 11
						39 00 00 40 00 00 03 BA 00 00
						39 00 00 40 00 00 03 BB 01 02
						39 00 00 40 00 00 04 FF 5A A5 01
						15 00 00 40 00 00 02 FB 08
						39 00 00 40 00 00 04 FF 5A A5 00
						15 00 00 40 00 00 02 5E 01
						15 00 00 40 00 00 02 60 00
						15 00 00 40 00 00 02 61 07
						15 00 00 40 00 00 02 35 00
						15 00 00 40 00 00 02 53 20
						39 00 00 40 00 00 04 FF 5A A5 00
						15 00 00 40 00 00 02 60 00
						39 00 00 40 00 00 04 FF 5A A5 53
						39 00 00 40 00 00 03 85 CC E1
						39 00 00 40 00 00 04 FF 5A A5 2D
						39 00 00 40 00 00 03 83 01 00
						15 00 00 40 00 00 02 F2 01
						39 00 00 00 00 00 04 FF 5A A5 00
						15 00 00 00 78 00 02 11 00 // Sleep OUT
						15 00 00 00 00 00 02 29 00 // Display ON
				];

				qcom,mdss-dsi-adfr-auto-on-command = [
					/* SDC Auto On */
				];
				qcom,mdss-dsi-adfr-auto-off-command = [
					/* SDC Auto Off */
				];

				qcom,mdss-dsi-post-on-backlight = [

				];

				qcom,mdss-dsi-panel-read-register-open-command = [
				];
				qcom,mdss-dsi-panel-read-register-close-command = [
				];

				qcom,mdss-dsi-temperature-compensation-command = [
				];
				qcom,mdss-dsi-read-compensation-reg1-command = [
				];

				qcom,mdss-dsi-pwm-switch-mode0-command = [
                                        39 00 00 40 00 00 04 FF 5A A5 00
                                        15 00 00 40 00 00 02 60 00
                                        39 00 00 00 00 00 04 FF 5A A5 00
                                ];

                                qcom,mdss-dsi-pwm-switch-mode1-command = [
                                        39 00 00 40 00 00 04 FF 5A A5 00
                                        15 00 00 40 00 00 02 60 01
                                        39 00 00 00 00 00 04 FF 5A A5 00
                                ];

				qcom,mdss-dsi-adfr-min-fps-0-command = [
					//60Hz
					39 00 00 40 00 00 04 FF 5A A5 2D
					39 00 00 40 00 00 03 83 01 00
					39 00 00 40 00 00 03 84 01 00
					39 00 00 00 00 00 04 FF 5A A5 00
				];
				qcom,mdss-dsi-adfr-min-fps-1-command = [
					//30Hz
					39 00 00 40 00 00 04 FF 5A A5 2D
					39 00 00 40 00 00 03 83 03 00
					39 00 00 40 00 00 03 84 03 00
					39 00 00 00 00 00 04 FF 5A A5 00
				];
				qcom,mdss-dsi-adfr-min-fps-2-command = [
					//20Hz
					39 00 00 40 00 00 04 FF 5A A5 2D
					39 00 00 40 00 00 03 83 05 00
					39 00 00 40 00 00 03 84 05 00
					39 00 00 00 00 00 04 FF 5A A5 00
				];
				qcom,mdss-dsi-adfr-min-fps-3-command = [
					//10Hz
					39 00 00 40 00 00 04 FF 5A A5 2D
					39 00 00 40 00 00 03 83 0B 00
					39 00 00 40 00 00 03 84 0B 00
					39 00 00 00 00 00 04 FF 5A A5 00
				];
				qcom,mdss-dsi-adfr-min-fps-4-command = [
					//5Hz
					39 00 00 40 00 00 04 FF 5A A5 2D
					39 00 00 40 00 00 03 83 17 00
					39 00 00 40 00 00 03 84 17 00
					39 00 00 00 00 00 04 FF 5A A5 00
				];
				qcom,mdss-dsi-adfr-min-fps-5-command = [
					//1Hz
					39 00 00 40 00 00 04 FF 5A A5 2D
					39 00 00 40 00 00 03 83 77 00
					39 00 00 40 00 00 03 84 77 00
					39 00 00 00 00 00 04 FF 5A A5 00
				];

				qcom,mdss-dsi-timing-switch-command-state = "dsi_hs_sync1_mode";
				qcom,mdss-dsi-timing-switch-high-fre-command-state = "dsi_hs_mode";
				qcom,mdss-dsi-on-command-state = "dsi_lp_mode";
				qcom,mdss-dsi-on-high-fre-command-state = "dsi_lp_mode";
				qcom,mdss-dsi-nolp-hpwm-command-state = "dsi_lp_sync1_mode";
				qcom,mdss-dsi-panel-read-register-open-state = "dsi_lp_mode";
				qcom,mdss-dsi-panel-read-register-close-state = "dsi_lp_mode";
				qcom,mdss-dsi-reset-scanline-command-state = "dsi_hs_mode";
				qcom,mdss-dsi-recovery-scanline-command-state = "dsi_hs_mode";

				qcom,mdss-dsi-adfr-auto-on-command-state ="dsi_hs_mode";
				qcom,mdss-dsi-adfr-auto-off-command-state ="dsi_hs_mode";
				qcom,mdss-dsi-temperature-compensation-command-state = "dsi_hs_mode";
				qcom,mdss-dsi-read-compensation-reg1-command-state = "dsi_hs_mode";
				qcom,mdss-dsi-lpwm-pulse-command-state = "dsi_hs_mode";
				qcom,mdss-dsi-hpwm-pulse-command-state = "dsi_hs_mode";
				qcom,mdss-dsi-pwm-switch-high-command-state = "dsi_hs_sync1_mode";
				qcom,mdss-dsi-pwm-switch-low-command-state = "dsi_hs_sync1_mode";
				qcom,mdss-dsi-power-on-pwm-switch-onepulse-command-state = "dsi_hs_mode";
				qcom,mdss-dsi-pwm-switch-1ptodc-command-state = "dsi_hs_sync1_mode";
				qcom,mdss-dsi-pwm-switch-dcto1p-command-state = "dsi_hs_sync1_mode";
				qcom,mdss-dsi-pwm-switch-1ptohp-command-state = "dsi_hs_sync1_mode";
				qcom,mdss-dsi-pwm-switch-hpto1p-command-state = "dsi_hs_sync1_mode";
				qcom,mdss-dsi-timming-pwm-switch-onepulse-command-state = "dsi_hs_sync1_mode";
				qcom,mdss-dsi-osc-track-on-command-state = "dsi_hs_mode";
				qcom,mdss-dsi-osc-track-off-command-state = "dsi_hs_mode";
				qcom,mdss-dsi-hbm-max-command-state = "dsi_hs_mode";
				qcom,mdss-dsi-hbm-exit-max-command-state = "dsi_hs_mode";

				qcom,mdss-dsi-pwm-switch-1to3-command-state = "dsi_hs_mode";
				qcom,mdss-dsi-pwm-switch-3to1-command-state = "dsi_hs_mode";


				qcom,mdss-dsi-adfr-min-fps-0-command-state = "dsi_hs_mode";
				qcom,mdss-dsi-adfr-min-fps-1-command-state = "dsi_hs_mode";
				qcom,mdss-dsi-adfr-min-fps-2-command-state = "dsi_hs_mode";
				qcom,mdss-dsi-adfr-min-fps-3-command-state = "dsi_hs_mode";
				qcom,mdss-dsi-adfr-min-fps-4-command-state = "dsi_hs_mode";
				qcom,mdss-dsi-adfr-min-fps-5-command-state = "dsi_hs_mode";
				qcom,mdss-dsi-adfr-min-fps-6-command-state = "dsi_hs_mode";
				qcom,lm-split = <632 632>;
				qcom,compression-mode = "dsc";
				qcom,mdss-dsc-encoders = <2>;
				qcom,mdss-dsc-slice-height = <20>;
				qcom,mdss-dsc-slice-width = <632>;
				qcom,mdss-dsc-slice-per-pkt = <2>;
				qcom,mdss-dsc-bit-per-component = <10>;
				qcom,mdss-dsc-bit-per-pixel = <8>;
				qcom,mdss-dsc-block-prediction-enable;
				qcom,mdss-dsi-panel-id1-command-state = "dsi_lp_mode";
			};
			timing@oa_fhd_120 {
				#include "dsi-panel-AE035-P-3-A0020-dsc-cmd-common.dtsi"
				qcom,mdss-mdp-transfer-time-us = <6290>;
				qcom,mdss-dsi-panel-jitter = <0x4 0x1>;
				qcom,mdss-dsc-version = <0x12>;
				qcom,mdss-dsi-timing-default;
				qcom,mdss-dsi-panel-framerate = <120>;
				qcom,mdss-dsi-panel-clockrate = <1112000000>;

				/* standard adfr */
				qcom,mdss-dsi-h-sync-skew = <2>;
				oplus,adfr-min-fps-mapping-table = <120 30>;

				// oplus,ofp-need-to-sync-data-in-aod-unlocking;
				// oplus,ofp-aod-off-insert-black-frame = <1>;
				// oplus,ofp-aod-off-black-frame-total-time = <42>;
				// oplus,ofp-need-to-separate-backlight;
				// oplus,ofp-backlight-on-period = <1>;

				qcom,mdss-dsi-panel-id1-command = [

				];

                                qcom,mdss-dsi-pwm-timing-switch-l1-command = [
                                                39 00 00 40 00 00 04 FF 5A A5 00
                                                15 00 00 40 00 00 02 60 00
                                                39 00 00 40 00 00 04 FF 5A A5 2D
                                                39 00 00 40 00 00 03 83 00 00
                                                15 00 00 40 00 00 02 F2 00
                                                39 00 00 00 00 00 04 FF 5A A5 00
                                ];

                                qcom,mdss-dsi-pwm-timing-switch-l2-command = [
                                                39 00 00 40 00 00 04 FF 5A A5 00
                                                15 00 00 40 00 00 02 60 01
                                                39 00 00 40 00 00 04 FF 5A A5 2D
                                                39 00 00 40 00 00 03 84 00 00
                                                15 00 00 40 00 00 02 F2 00
                                                39 00 00 00 00 00 04 FF 5A A5 00
                                ];

				qcom,mdss-dsi-on-command = [
						39 00 00 40 00 00 04 FF 5A A5 08
						15 00 00 40 00 00 02 C8 62 // Sleep out don't reload
							/* PPS setting */
						39 00 00 40 00 00 04 FF 5A A5 07
						15 00 00 40 00 00 02 8A 01 // PPS Enable
						39 00 00 40 00 00 03 8B 11 E0 // PPS Table
						39 00 00 40 00 00 64 81 00 00 00 00 00 12 00
											00 AB 30 80 0A DC 04 F0
											00 14 02 78 02 78 02 00
											02 57 00 20 01 F8 00 08
											00 0D 05 7A 04 4F 18 00
											10 E0 07 10 20 00 06 0F
											0F 33 0E 1C 2A 38 46 54
											62 69 70 77 79 7B 7D 7E
											02 02 22 00 2A 40 2A BE
											3A FC 3A FA 3A F8 3B 38
											3B 78 3B B6 4B B6 4B F4
											4B F4 6C 34 84 74 00 00
											00 00 00 00
						39 00 00 40 00 00 04 FF 5A A5 21
						15 00 00 40 00 00 02 A4 18 // Flash reload enable
						/* ODC Compensation */
						39 00 00 40 00 00 04 FF 5A A5 49
						39 00 00 40 00 00 11 81 10 00 F3 01 3B 02 45 02 45 02 A9 03 8D 05 DD 06
						15 00 00 40 00 00 02 E0 01
						39 00 00 40 00 00 04 FF 5A A5 5A
						39 00 00 40 00 00 04 80 00 00 00
						39 00 00 40 00 00 04 81 19 25 1B
						39 00 00 40 00 00 04 82 10 20 14
						39 00 00 40 00 00 04 83 03 12 03
						39 00 00 40 00 00 04 84 01 0A 04
						39 00 00 40 00 00 04 85 01 0A 00
						39 00 00 40 00 00 04 86 02 22 12
						39 00 00 40 00 00 04 87 02 1C 0A
						39 00 00 40 00 00 04 88 02 16 08
						39 00 00 40 00 00 04 89 00 0A 08
						39 00 00 40 00 00 04 8A 01 24 20
						39 00 00 40 00 00 04 8B 01 1D 11
						39 00 00 40 00 00 04 8C 00 15 10
						39 00 00 40 00 00 04 8D 00 0E 0C
						39 00 00 40 00 00 04 8E 00 07 09
						39 00 00 40 00 00 04 8F 00 25 28
						39 00 00 40 00 00 04 90 02 1C 16
						39 00 00 40 00 00 04 91 02 12 14
						39 00 00 40 00 00 04 92 01 08 12
						39 00 00 40 00 00 04 93 01 06 0F
						39 00 00 40 00 00 04 94 00 03 02
						39 00 00 40 00 00 04 95 02 28 26
						39 00 00 40 00 00 04 96 02 22 24
						39 00 00 40 00 00 04 97 03 15 1E
						39 00 00 40 00 00 04 98 01 12 18
						39 00 00 40 00 00 04 99 01 07 16
						39 00 00 40 00 00 04 9A 01 05 0A
						39 00 00 40 00 00 04 9B 01 03 06
						39 00 00 40 00 00 04 A4 FA 01 FA
						39 00 00 40 00 00 04 A5 F9 02 FB
						39 00 00 40 00 00 04 A6 FB 01 FA
						39 00 00 40 00 00 04 A7 FC 02 FD
						39 00 00 40 00 00 04 A8 FA 01 FA
						39 00 00 40 00 00 04 A9 F8 00 FA
						39 00 00 40 00 00 04 AA 0C 0D 0F
						39 00 00 40 00 00 04 AB 07 05 06
						39 00 00 40 00 00 04 AC 06 04 05
						39 00 00 40 00 00 04 AD 03 02 03
						39 00 00 40 00 00 04 B3 22 28 26
						39 00 00 40 00 00 04 B4 16 1A 18
						39 00 00 40 00 00 04 B5 12 16 14
						39 00 00 40 00 00 04 B6 07 0D 0F
						39 00 00 40 00 00 04 B7 02 03 04
						39 00 00 40 00 00 04 B8 00 01 01
						39 00 00 40 00 00 04 B9 23 2A 27
						39 00 00 40 00 00 04 BA 19 1D 1B
						39 00 00 40 00 00 04 BB 14 1A 16
						39 00 00 40 00 00 04 BC 0C 10 0F
						39 00 00 40 00 00 04 BD 06 0B 0A
						39 00 00 40 00 00 04 BE 03 04 03
						39 00 00 40 00 00 04 BF 02 03 02
						39 00 00 40 00 00 04 C8 01 03 02
						39 00 00 40 00 00 04 C9 01 06 06
						39 00 00 40 00 00 04 CB 05 0B 09
						39 00 00 40 00 00 04 CC 01 02 01
						39 00 00 40 00 00 04 CD 00 01 01
						39 00 00 40 00 00 04 D7 1D 23 21
						39 00 00 40 00 00 04 D8 1A 1D 1A
						39 00 00 40 00 00 04 D9 14 18 16
						39 00 00 40 00 00 04 DA 03 07 0A
						39 00 00 40 00 00 04 DB 03 04 06
						39 00 00 40 00 00 04 DC 00 01 01
						39 00 00 40 00 00 04 DD 20 26 24
						39 00 00 40 00 00 04 DE 20 23 22
						39 00 00 40 00 00 04 DF 1A 1D 1C
						39 00 00 40 00 00 04 E0 12 14 16
						39 00 00 40 00 00 04 E1 09 0C 0D
						39 00 00 40 00 00 04 E2 02 03 05
						39 00 00 40 00 00 04 E3 01 02 03
						39 00 00 40 00 00 04 FF 5A A5 5B
						39 00 00 40 00 00 04 81 03 0A 09
						39 00 00 40 00 00 04 82 00 00 00
						39 00 00 40 00 00 04 83 05 0B 09
						39 00 00 40 00 00 04 8F 1E 24 22
						39 00 00 40 00 00 04 90 12 16 18
						39 00 00 40 00 00 04 91 0D 10 14
						39 00 00 40 00 00 04 92 06 09 12
						39 00 00 40 00 00 04 93 04 06 0C
						39 00 00 40 00 00 04 94 00 01 01
						39 00 00 40 00 00 04 95 20 26 24
						39 00 00 40 00 00 04 96 12 14 2F
						39 00 00 40 00 00 04 97 10 12 20
						39 00 00 40 00 00 04 98 0A 0C 1A
						39 00 00 40 00 00 04 99 06 08 13
						39 00 00 40 00 00 04 9A 04 04 08
						39 00 00 40 00 00 04 9B 03 03 06
						39 00 00 40 00 00 04 A5 03 09 07
						39 00 00 40 00 00 04 A6 00 00 00
						39 00 00 40 00 00 04 A7 05 0A 08
						39 00 00 40 00 00 04 B3 1E 24 22
						39 00 00 40 00 00 04 B4 12 16 18
						39 00 00 40 00 00 04 B5 0D 11 14
						39 00 00 40 00 00 04 B6 06 0A 10
						39 00 00 40 00 00 04 B7 04 07 0A
						39 00 00 40 00 00 04 B8 00 01 01
						39 00 00 40 00 00 04 B9 20 26 24
						39 00 00 40 00 00 04 BA 12 15 20
						39 00 00 40 00 00 04 BB 10 13 18
						39 00 00 40 00 00 04 BC 0A 0D 12
						39 00 00 40 00 00 04 BD 06 08 0A
						39 00 00 40 00 00 04 BE 02 05 08
						39 00 00 40 00 00 04 BF 02 03 06
						39 00 00 40 00 00 04 C9 04 06 05
						39 00 00 40 00 00 04 D4 08 0A 13
						39 00 00 40 00 00 04 D5 06 06 0D
						39 00 00 40 00 00 04 D6 02 02 07
						39 00 00 40 00 00 04 D7 15 1A 1A
						39 00 00 40 00 00 04 D8 12 13 18
						39 00 00 40 00 00 04 D9 0F 11 17
						39 00 00 40 00 00 04 DA 09 0B 10
						39 00 00 40 00 00 04 DB 02 03 08
						39 00 00 40 00 00 04 DC 00 01 01
						39 00 00 40 00 00 04 DD 2F 25 23
						39 00 00 40 00 00 04 DE 13 14 16
						39 00 00 40 00 00 04 DF 12 13 1E
						39 00 00 40 00 00 04 E0 10 12 16
						39 00 00 40 00 00 04 E1 0B 0E 11
						39 00 00 40 00 00 04 E2 03 04 07
						39 00 00 40 00 00 04 E3 02 03 05
						39 00 00 40 00 00 04 FF 5A A5 5C
						39 00 00 40 00 00 04 81 03 06 07
						39 00 00 40 00 00 04 8F 1B 22 20
						39 00 00 40 00 00 04 90 14 17 13
						39 00 00 40 00 00 04 91 0B 10 12
						39 00 00 40 00 00 04 92 03 06 0D
						39 00 00 40 00 00 04 93 02 03 06
						39 00 00 40 00 00 04 94 00 01 01
						39 00 00 40 00 00 04 95 1E 24 22
						39 00 00 40 00 00 04 96 11 13 1C
						39 00 00 40 00 00 04 97 10 12 16
						39 00 00 40 00 00 04 98 07 0A 13
						39 00 00 40 00 00 04 99 05 08 0A
						39 00 00 40 00 00 04 9A 01 02 04
						39 00 00 40 00 00 04 9B 00 01 03
						39 00 00 40 00 00 04 AE 16 19 16
						39 00 00 40 00 00 04 B3 1A 20 1E
						39 00 00 40 00 00 04 B4 12 14 12
						39 00 00 40 00 00 04 B5 10 12 13
						39 00 00 40 00 00 04 B6 06 08 0A
						39 00 00 40 00 00 04 B7 03 04 06
						39 00 00 40 00 00 04 B8 00 01 01
						39 00 00 40 00 00 04 B9 14 1A 18
						39 00 00 40 00 00 04 BA 12 14 14
						39 00 00 40 00 00 04 BB 10 12 13
						39 00 00 40 00 00 04 BC 08 0D 11
						39 00 00 40 00 00 04 BD 03 04 0B
						39 00 00 40 00 00 04 BE 02 02 04
						39 00 00 00 00 00 04 BF 02 03 03
						/* Crosstalk Compensation */
						39 00 00 40 00 00 04 FF 5A A5 31
						15 00 00 00 01 00 02 D0 81
						39 00 00 40 00 00 13 80 F0 99 62 25 02 FE DB 9E 67 E0 1A 17 16 00 00 E3 C8 C4
						39 00 00 40 00 00 13 81 F0 9C 65 25 02 FE DB 9B 64 E0 09 08 05 00 00 FD F4 EC
						39 00 00 40 00 00 13 82 F0 81 53 1F 02 FE E1 AD 7F E0 07 06 05 00 00 FD FC FB
						39 00 00 40 00 00 13 83 F0 70 48 1B 02 FE E5 B8 90 E0 07 06 05 00 00 FD FC FB
						39 00 00 40 00 00 13 84 F0 94 60 23 02 FE DD A0 6C E0 06 05 04 00 00 FB FA F9
						39 00 00 40 00 00 13 85 F0 7C 50 1E 02 FE E2 B0 84 E0 06 05 04 00 00 FB FA F9
						39 00 00 40 00 00 13 86 F0 99 62 25 02 FE DB 9E 67 E0 1A 17 16 00 00 E3 C8 C4
						39 00 00 40 00 00 13 87 F0 9C 65 25 02 FE DB 9B 64 E0 09 08 05 00 00 FD F4 EC
						39 00 00 40 00 00 13 88 F0 81 53 1F 02 FE E1 AD 7F E0 07 06 05 00 00 FD FC FB
						39 00 00 40 00 00 13 89 F0 70 48 1B 02 FE E5 B8 90 E0 07 06 05 00 00 FD FC FB
						39 00 00 40 00 00 13 8A F0 94 60 23 02 FE DD A0 6C E0 06 05 04 00 00 FB FA F9
						39 00 00 00 01 00 13 8B F0 7C 50 1E 02 FE E2 B0 84 E0 06 05 04 00 00 FB FA F9
						15 00 00 40 00 00 02 D0 80
						39 00 00 40 00 00 04 FF 5A A5 31
						15 00 00 40 00 00 02 9F 06
						15 00 00 40 00 00 02 A3 18
						15 00 00 40 00 00 02 A5 10
						39 00 00 40 00 00 19 8C 14 12 0E 0C 06 00 00 00 00 00 00 00 00 00 00 00 00 00 00 00 00 00 00 00
						39 00 00 40 00 00 1A 8D 06 05 05 04 04 00 00 00 00 00 00 00 00 00 00 00 00 00 00 00 00 00 00 00 80
						39 00 00 40 00 00 0B 90 01 02 04 05 09 01 02 04 05 09
						39 00 00 40 00 00 07 91 04 44 55 01 01 03
						39 00 00 40 00 00 07 92 04 44 55 01 01 03
						39 00 00 40 00 00 07 93 04 44 55 01 01 03
						39 00 00 40 00 00 09 8F 40 40 40 40 40 40 40 40
						15 00 00 40 00 00 02 A6 00
						15 00 00 40 00 00 02 A7 10
						15 00 00 40 00 00 02 A8 00
						15 00 00 40 00 00 02 A9 10
						15 00 00 40 00 00 02 AA 00
						15 00 00 40 00 00 02 AB 10
						15 00 00 40 00 00 02 A0 A3
						39 00 00 40 00 00 04 FF 5A A5 07
						15 00 00 40 00 00 02 E5 05
						39 00 00 40 00 00 07 E0 00 F0 06 DD 07 FF
						39 00 00 40 00 00 04 FF 5A A5 2B
						39 00 00 40 00 00 05 AA 30 F7 00 00
						39 00 00 40 00 00 05 AD 30 F9 00 00
						39 00 00 40 00 00 05 B0 30 FA 00 00
						39 00 00 40 00 00 05 B3 30 FC 00 00
						39 00 00 40 00 00 05 C4 0F 04 FB F1
						39 00 00 40 00 00 05 C5 3F DE E4 E4
						39 00 00 40 00 00 05 C7 3F F8 FD F5
						39 00 00 40 00 00 05 C8 3F E2 E9 E9
						39 00 00 40 00 00 05 CA 0F 02 FA F3
						39 00 00 40 00 00 05 CB 3F ED EF ED
						39 00 00 40 00 00 05 CD 03 02 00 FB
						39 00 00 40 00 00 05 DF 0F 04 F1 F6
						39 00 00 40 00 00 05 E0 3F D2 EB EE
						39 00 00 40 00 00 05 E2 3F F5 F0 F8
						39 00 00 40 00 00 05 E3 3F E2 EE E2
						39 00 00 40 00 00 05 E6 3F FE F3 F4
						39 00 00 40 00 00 05 E9 3F FD F7 F5
						39 00 00 40 00 00 05 EC 3F FD FA F7
						39 00 00 00 00 00 04 FF 5A A5 00
						/* Gamma Correction */
                                                39 00 00 40 00 00 04 FF 5A A5 2F
                                                15 00 00 40 00 00 02 99 80
                                                39 00 00 40 00 00 04 FF 5A A5 1F
                                                15 00 00 40 00 00 02 B2 00
                                                39 00 00 40 00 00 04 FF 5A A5 6E
                                                39 00 00 40 00 00 05 B8 00 5A 00 66
                                                39 00 00 40 00 00 05 B9 00 65 00 71
                                                39 00 00 40 00 00 05 BA 00 40 00 6F
                                                39 00 00 40 00 00 05 BB 00 6A 00 5B
                                                39 00 00 40 00 00 05 BC 00 62 00 65
                                                39 00 00 40 00 00 05 BD 00 62 00 5B
                                                39 00 00 40 00 00 05 BE 00 5A 00 58
                                                39 00 00 40 00 00 05 BF 00 5A 00 56
                                                39 00 00 40 00 00 05 C0 00 7D 00 7B
                                                39 00 00 40 00 00 05 C1 00 76 00 75
                                                39 00 00 40 00 00 05 C2 00 40 00 6F
                                                39 00 00 40 00 00 05 C3 00 65 00 54
                                                39 00 00 40 00 00 05 C4 00 50 00 4C
                                                39 00 00 40 00 00 05 C5 00 46 00 3C
                                                39 00 00 40 00 00 05 C6 00 38 00 35
                                                39 00 00 40 00 00 05 C7 00 32 00 2A
                                                39 00 00 40 00 00 05 C8 00 44 00 4E
                                                39 00 00 40 00 00 05 C9 00 50 00 52
                                                39 00 00 40 00 00 05 CA 00 40 00 4F
                                                39 00 00 40 00 00 05 CB 00 4F 00 42
                                                39 00 00 40 00 00 05 CC 00 41 00 41
                                                39 00 00 40 00 00 05 CD 00 3F 00 3E
                                                39 00 00 40 00 00 05 CE 00 3E 00 3D
                                                39 00 00 40 00 00 05 CF 00 3C 00 37
                                                39 00 00 40 00 00 05 D0 00 57 00 4D
                                                39 00 00 40 00 00 05 D1 00 4B 00 49
                                                39 00 00 40 00 00 05 D2 00 40 00 41
                                                39 00 00 40 00 00 05 D3 00 3F 00 34
                                                39 00 00 40 00 00 05 D4 00 32 00 2F
                                                39 00 00 40 00 00 05 D5 00 2B 00 2A
                                                39 00 00 40 00 00 05 D6 00 29 00 28
                                                39 00 00 40 00 00 05 D7 00 25 00 20
                                                39 00 00 40 00 00 04 FF 5A A5 24
                                                15 00 00 40 00 00 02 A1 01
                                                15 00 00 40 00 00 02 A2 E0
                                                15 00 00 40 00 00 02 A3 00
                                                39 00 00 40 00 00 0D A4 44 44 42 27 71 11 06 33 35 55 55 22
                                                39 00 00 40 00 00 1B D0 10 ED 0F FE 0D BB 0B 1A 07 52 04 8B 04 8A 04 76 03 E6 02 CB 01 E1 00 01 00 00
                                                39 00 00 40 00 00 04 FF 5A A5 1F
                                                15 00 00 40 00 00 02 B2 00
                                                39 00 00 40 00 00 04 FF 5A A5 6B
                                                39 00 00 40 00 00 05 95 74 88 4C 86
                                                39 00 00 40 00 00 05 96 11 A7 4D 71
                                                39 00 00 40 00 00 05 97 32 9E 4F B0
                                                39 00 00 40 00 00 05 98 10 C7 4B 38
                                                39 00 00 40 00 00 05 99 51 B9 4C 62
                                                39 00 00 40 00 00 05 9A BA DF 4F E9
                                                39 00 00 40 00 00 05 9B F8 2C 48 E0
                                                39 00 00 40 00 00 05 9C DA 29 46 B2
                                                39 00 00 40 00 00 05 9D 75 13 42 63
                                                39 00 00 40 00 00 05 9E BF 60 43 58
						39 00 00 40 00 00 05 9F 6A 82 46 1C
                                                39 00 00 40 00 00 05 A0 9D E8 4D 7E
                                                39 00 00 40 00 00 05 B9 74 88 4C 86
                                                39 00 00 40 00 00 05 BA 11 A7 4D 71
                                                39 00 00 40 00 00 05 BB 32 9E 4F B0
                                                39 00 00 40 00 00 05 BC 10 C7 4B 38
                                                39 00 00 40 00 00 05 BD 51 B9 4C 62
                                                39 00 00 40 00 00 05 BE BA DF 4F E9
                                                39 00 00 40 00 00 05 BF F8 2C 48 E0
                                                39 00 00 40 00 00 05 C0 DA 29 46 B2
                                                39 00 00 40 00 00 05 C1 75 13 42 63
                                                39 00 00 40 00 00 05 C2 BF 60 43 58
                                                39 00 00 40 00 00 05 C3 6A 82 46 1C
                                                39 00 00 40 00 00 05 C4 9D E8 4D 7E
                                                39 00 00 40 00 00 04 FF 5A A5 6C
                                                39 00 00 40 00 00 05 89 44 DF 41 F4
                                                39 00 00 40 00 00 05 8A 44 24 46 44
                                                39 00 00 40 00 00 05 8B 44 83 43 64
                                                39 00 00 40 00 00 05 8C 62 B7 44 69
                                                39 00 00 40 00 00 05 8D 76 B8 4B 77
                                                39 00 00 40 00 00 05 8E 48 AD 4E B7
                                                39 00 00 40 00 00 05 8F 32 03 43 3F
                                                39 00 00 40 00 00 05 90 33 73 42 30
                                                39 00 00 40 00 00 05 91 33 00 40 22
                                                39 00 00 40 00 00 05 92 DF 60 42 69
                                                39 00 00 40 00 00 05 93 6D 81 45 1D
                                                39 00 00 40 00 00 05 94 78 D7 4B 6A
                                                39 00 00 40 00 00 05 AD 44 DF 41 F4
                                                39 00 00 40 00 00 05 AE 44 24 46 44
                                                39 00 00 40 00 00 05 AF 44 83 43 64
                                                39 00 00 40 00 00 05 B0 62 B7 44 69
                                                39 00 00 40 00 00 05 B1 76 B8 4B 77
                                                39 00 00 40 00 00 05 B2 48 AD 4E B7
                                                39 00 00 40 00 00 05 B3 32 03 43 3F
                                                39 00 00 40 00 00 05 B4 33 73 42 30
                                                39 00 00 40 00 00 05 B5 33 00 40 22
                                                39 00 00 40 00 00 05 B6 DF 60 42 69
                                                39 00 00 40 00 00 05 B7 6D 81 45 1D
                                                39 00 00 40 00 00 05 B8 78 D7 4B 6A
                                                39 00 00 40 00 00 04 FF 5A A5 2F
                                                15 00 00 40 00 00 02 99 00
                                                39 00 00 40 00 00 04 FF 5A A5 00
						39 00 00 40 00 00 04 FF 5A A5 28
                                                39 00 00 40 00 00 05 CA 0F 02 FA F3
                                                39 00 00 40 00 00 04 FF 5A A5 06
                                                15 00 00 40 00 00 02 98 04
						/* decreasing step */
						39 00 00 40 00 00 04 FF 5A A5 2D
						15 00 00 40 00 00 02 97 03
						15 00 00 40 00 00 02 B1 03
						39 00 00 40 00 00 03 98 03 00
						39 00 00 40 00 00 03 99 05 00
						39 00 00 40 00 00 03 9A 0B 00
						39 00 00 40 00 00 03 9B 17 00
						39 00 00 40 00 00 03 A0 00 00
						39 00 00 40 00 00 03 A1 01 02
						15 00 00 40 00 00 02 B2 02
						15 00 00 40 00 00 02 B3 04
						15 00 00 40 00 00 02 B4 08
						15 00 00 40 00 00 02 B5 11
						39 00 00 40 00 00 03 BA 00 00
						39 00 00 40 00 00 03 BB 01 02
						39 00 00 40 00 00 04 FF 5A A5 01
						15 00 00 40 00 00 02 FB 08
						39 00 00 40 00 00 04 FF 5A A5 00
						15 00 00 40 00 00 02 5E 01
						15 00 00 40 00 00 02 60 00
						15 00 00 40 00 00 02 61 07
						15 00 00 40 00 00 02 35 00
						15 00 00 40 00 00 02 53 20
						39 00 00 40 00 00 04 FF 5A A5 00
						15 00 00 40 00 00 02 60 00
						39 00 00 40 00 00 04 FF 5A A5 53
						39 00 00 40 00 00 03 85 CC E1
						39 00 00 40 00 00 04 FF 5A A5 2D
						39 00 00 40 00 00 03 83 00 00
						15 00 00 40 00 00 02 F2 00
						39 00 00 00 00 00 04 FF 5A A5 00
						15 00 00 00 78 00 02 11 00 // Sleep OUT
						15 00 00 00 00 00 02 29 00 // Display ON
				];

				qcom,mdss-dsi-adfr-auto-on-command = [
					/* SDC Auto On */
				];
				qcom,mdss-dsi-adfr-auto-off-command = [
					/* SDC Auto Off */
				];

				qcom,mdss-dsi-post-on-backlight = [

				];

				qcom,mdss-dsi-panel-read-register-open-command = [
				];
				qcom,mdss-dsi-panel-read-register-close-command = [
				];

				qcom,mdss-dsi-temperature-compensation-command = [
				];
				qcom,mdss-dsi-read-compensation-reg1-command = [
				];

				qcom,mdss-dsi-pwm-switch-mode0-command = [
                                        39 00 00 40 00 00 04 FF 5A A5 00
                                        15 00 00 40 00 00 02 60 00
                                        39 00 00 00 00 00 04 FF 5A A5 00
                                ];

                                qcom,mdss-dsi-pwm-switch-mode1-command = [
                                        39 00 00 40 00 00 04 FF 5A A5 00
                                        15 00 00 40 00 00 02 60 01
                                        39 00 00 00 00 00 04 FF 5A A5 00
                                ];

                                qcom,mdss-dsi-adfr-min-fps-0-command = [
                                        //120Hz
                                        39 00 00 40 00 00 04 FF 5A A5 2D
                                        39 00 00 40 00 00 03 83 00 00
                                        39 00 00 40 00 00 03 84 00 00
                                        39 00 00 40 00 00 04 FF 5A A5 02
                                        39 00 00 40 00 00 05 B0 00 80 00 10
                                        39 00 00 00 00 00 04 FF 5A A5 00
                                ];
                                qcom,mdss-dsi-adfr-min-fps-1-command = [
                                        //60Hz
                                        39 00 00 40 00 00 04 FF 5A A5 2D
                                        39 00 00 40 00 00 03 83 03 00
                                        39 00 00 40 00 00 03 84 03 00
                                        39 00 00 40 00 00 04 FF 5A A5 02
                                        39 00 00 40 00 00 05 B0 00 88 00 10
                                        39 00 00 00 00 00 04 FF 5A A5 00
                                ];

				qcom,mdss-dsi-timing-switch-command-state = "dsi_hs_sync1_mode";
				qcom,mdss-dsi-timing-switch-high-fre-command-state = "dsi_hs_mode";
				qcom,mdss-dsi-on-command-state = "dsi_lp_mode";
				qcom,mdss-dsi-on-high-fre-command-state = "dsi_lp_mode";
				qcom,mdss-dsi-nolp-hpwm-command-state = "dsi_lp_sync1_mode";
				qcom,mdss-dsi-panel-read-register-open-state = "dsi_lp_mode";
				qcom,mdss-dsi-panel-read-register-close-state = "dsi_lp_mode";
				qcom,mdss-dsi-reset-scanline-command-state = "dsi_hs_mode";
				qcom,mdss-dsi-recovery-scanline-command-state = "dsi_hs_mode";

				qcom,mdss-dsi-adfr-auto-on-command-state ="dsi_hs_mode";
				qcom,mdss-dsi-adfr-auto-off-command-state ="dsi_hs_mode";
				qcom,mdss-dsi-temperature-compensation-command-state = "dsi_hs_mode";
				qcom,mdss-dsi-read-compensation-reg1-command-state = "dsi_hs_mode";
				qcom,mdss-dsi-lpwm-pulse-command-state = "dsi_hs_mode";
				qcom,mdss-dsi-hpwm-pulse-command-state = "dsi_hs_mode";
				qcom,mdss-dsi-pwm-switch-high-command-state = "dsi_hs_sync1_mode";
				qcom,mdss-dsi-pwm-switch-low-command-state = "dsi_hs_sync1_mode";
				qcom,mdss-dsi-power-on-pwm-switch-onepulse-command-state = "dsi_hs_mode";
				qcom,mdss-dsi-pwm-switch-1ptodc-command-state = "dsi_hs_sync1_mode";
				qcom,mdss-dsi-pwm-switch-dcto1p-command-state = "dsi_hs_sync1_mode";
				qcom,mdss-dsi-pwm-switch-1ptohp-command-state = "dsi_hs_sync1_mode";
				qcom,mdss-dsi-pwm-switch-hpto1p-command-state = "dsi_hs_sync1_mode";
				qcom,mdss-dsi-timming-pwm-switch-onepulse-command-state = "dsi_hs_sync1_mode";
				qcom,mdss-dsi-osc-track-on-command-state = "dsi_hs_mode";
				qcom,mdss-dsi-osc-track-off-command-state = "dsi_hs_mode";
				qcom,mdss-dsi-hbm-max-command-state = "dsi_hs_mode";
				qcom,mdss-dsi-hbm-exit-max-command-state = "dsi_hs_mode";

				qcom,mdss-dsi-pwm-switch-1to3-command-state = "dsi_hs_mode";
				qcom,mdss-dsi-pwm-switch-3to1-command-state = "dsi_hs_mode";

				qcom,mdss-dsi-adfr-min-fps-0-command-state = "dsi_hs_mode";
				qcom,mdss-dsi-adfr-min-fps-1-command-state = "dsi_hs_mode";
				qcom,mdss-dsi-adfr-min-fps-2-command-state = "dsi_hs_mode";
				qcom,mdss-dsi-adfr-min-fps-3-command-state = "dsi_hs_mode";
				qcom,mdss-dsi-adfr-min-fps-4-command-state = "dsi_hs_mode";
				qcom,mdss-dsi-adfr-min-fps-5-command-state = "dsi_hs_mode";
				qcom,mdss-dsi-adfr-min-fps-6-command-state = "dsi_hs_mode";

				qcom,lm-split = <632 632>;
				qcom,compression-mode = "dsc";
				qcom,mdss-dsc-encoders = <2>;
				qcom,mdss-dsc-slice-height = <20>;
				qcom,mdss-dsc-slice-width = <632>;
				qcom,mdss-dsc-slice-per-pkt = <2>;
				qcom,mdss-dsc-bit-per-component = <10>;
				qcom,mdss-dsc-bit-per-pixel = <8>;
				qcom,mdss-dsc-block-prediction-enable;
				qcom,mdss-dsi-panel-id1-command-state = "dsi_lp_mode";
			};
		};
	};
};

&soc {
	dsi_panel_AE035_P_3_A0020_dsc_cmd {
		qcom,dsi-display-active;
	};
};

&dsi_panel_AE035_P_3_A0020_dsc_cmd {
	qcom,panel-supply-entries = <&oplus_dsi_panel_custom_pwr_supply>;
	qcom,mdss-dsi-panel-controller = <&mdss_dsi0>;
	qcom,mdss-dsi-bl-pmic-control-type = "bl_ctrl_dcs";
	qcom,bl-update-flag = "delay_until_first_frame";
	qcom,mdss-dsi-bl-min-level = <1>;
	qcom,mdss-dsi-bl-max-level = <4095>;
	qcom,mdss-brightness-max-level = <4095>;
	oplus,dsi-bl-normal-max-level = <3515>;
	oplus,dsi-brightness-normal-max-level = <3515>;
	oplus,dsi-dc-backlight-threshold = <1960>;
	oplus,dsi-brightness-default-level = <1638>;
	qcom,platform-te-gpio = <&tlmm 86 0>;
	qcom,dynamic-te-gpio = <&tlmm 85 0>;
	qcom,platform-reset-gpio = <&tlmm 98 0>;
	oplus,panel-gpio1 = <&pm8550ve_f_gpios 7 0>;

	oplus,panel-reset-position = <0x02>;
	oplus,panel-power-on-sequence = "10", "vddio", "10", "gpio1", "10", "vci", "10";
	oplus,panel-power-off-sequence = "10", "vci", "10", "gpio1", "10", "vddio", "10";

	qcom,mdss-dsi-bl-inverted-dbv;
	qcom,ulps-enabled;
	qcom,dsi-select-clocks = "pll_byte_clk0", "pll_dsi_clk0";
	/* ofp config */
	oplus,ofp-fp-type = <0x90>;
	oplus,ofp-need-to-wait-data-before-aod-on;
	oplus,ofp-need-to-update-lhbm-pressed-icon-gamma;

	/* adfr config */
	/* just for qsync enable*/
	 qcom,qsync-enable;
	 qcom,mdss-dsi-qsync-min-refresh-rate = <24>;
	/*
	** 0st bit: adfr global on/off
	** 1st bit: fakeframe on/off
	** 2st bit: switch on/off
	** 3rd bit: 0:double-TE switch 1:external TE/TP switch
	** 4rd bit: idle mode on/off
	** 5th bit: temperature compensation mode on/off
	*/
	 oplus,adfr-config = <0x1051>;  // 0b1110'0101'0001
	 oplus,adfr-test-te-gpio = <&tlmm 85 0>;

	// qcom,dsi-dyn-clk-enable;

	qcom,mdss-dsi-display-timings {
		timing@sa_fhd_120 { /* FHD+ 120hz 1094.4Mbps */
			qcom,mdss-dsi-panel-phy-timings = [00 24 0A 0A 1A 24 0A 0A 09 02 04 00 1E 0F];
			qcom,display-topology = <1 1 1>,<2 2 1>;
			qcom,default-topology-index = <1>;
			qcom,dsi-dyn-clk-list = <1112000000 1056000000>;
		};
		timing@sa_fhd_90 { /* FHD+ 120hz 1094.4Mbps */
			qcom,mdss-dsi-panel-phy-timings = [00 24 0A 0A 1A 24 0A 0A 09 02 04 00 1E 0F];
			qcom,display-topology = <1 1 1>,<2 2 1>;
			qcom,default-topology-index = <1>;
			qcom,dsi-dyn-clk-list = <1112000000 1056000000>;
		};
		timing@sa_fhd_60 { /* FHD+ 120hz 1094.4Mbps */
			qcom,mdss-dsi-panel-phy-timings = [00 24 0A 0A 1A 24 0A 0A 09 02 04 00 1E 0F];
			qcom,display-topology = <1 1 1>,<2 2 1>;
			qcom,default-topology-index = <1>;
			qcom,dsi-dyn-clk-list = <1112000000 1056000000>;
		};
		timing@oa_fhd_120 { /* FHD+ 120hz 1094.4Mbps */
			qcom,mdss-dsi-panel-phy-timings = [00 24 0A 0A 1A 24 0A 0A 09 02 04 00 1E 0F];
			qcom,display-topology = <1 1 1>,<2 2 1>;
			qcom,default-topology-index = <1>;
			qcom,dsi-dyn-clk-list = <1112000000 1056000000>;
		};


	};
};
&dsi_panel_AE035_P_3_A0020_dsc_cmd {
	qcom,panel_voltage_vddi_name = "vddio";
	qcom,panel_voltage_vddi = <0 1800000 1850000 1950000>;
	qcom,panel_voltage_vddr_name = "vddio";
	qcom,panel_voltage_vddr = <1 1800000 1850000 1950000>;
};

&dsi_panel_AE035_P_3_A0020_dsc_cmd{
	oplus,color_vivid_status;
	oplus,color_srgb_status;
	//oplus,color_softiris_status;
	oplus,color_dual_brightness_status;
	oplus,color_2nit_status;
	oplus,color_oplus_calibrate_status;
	oplus,color_samsung_status;
	oplus,color_loading_status;
	//oplus,color_nature_profession_status;
	oplus,mdss-dsi-panel-type = <0>;

	/* serial num config */
	oplus,dsi-serial-number-enabled;
	oplus,dsi-serial-number-switch-page;
	oplus,dsi-serial-number-index= <0x0>;
	oplus,dsi-serial-number-reg= <0x82>;
	oplus,dsi-serial-number-read-count= <7>;

	/* demura dbv config */
	//oplus,bl_denura-dbv-switch-support;

	/*Feature config*/
	//oplus,pwm-switch-support;
	//oplus,pwm-switch-restore-support;
	//oplus,pwm-switch-backlight-threshold = <1087>;
	//oplus,pwm-create-thread-disable-duty;
	//oplus,cmdq-sync-support;
	//oplus,dp-enabled;
};

&dsi_panel_AE035_P_3_A0020_dsc_cmd {
	/* demura dbv config */
	/* pwm config */
	/*	oplus,pwm-switch-config:
		Bit0: pwm feature enable
		Bit1: pwm mode switch enable, need to config switch cmds
		Bit2: force enabled pwm mode switch cmd, will send mode cmd even dbv threshold cmd feature is configed
		Bit3: pwm dbv threshold pulse switch enable, need to config threshold switch cmds
		Bit4: wait te before sending pwm dbv threshold pulse switch cmd
		Bit5: replace specific cmd to other cmd while in pwm 1pulse mode
		Bit6: sending extend cmd while panel power on accroding to current pwm mode
		Bit7: sending extend cmd while timing switch accroding to current pwm pulse level
		Bit8: sending extend cmd after sending dbv threshold cmd in another thread
	*/
	oplus,pwm-switch-config = <0x87>;
	/*	oplus,pwm-switch-mode0-states-info/oplus,pwm-switch-mode1-states-info:
		Specific dbv threshold and pulse info of 2 pwm mode, for pulse, 0 symbols 1pulse,
		1symbols 3pulse and 2 symbols 18pulse. The format should be 1 dbv threshold info with
		2 pwm pulse levels left and right(for example, <2 1087 1> means 18pulse while dbv <= 1087
		and 3pulse while dbv > 1087), or only one pulse level, no threshold.
	*/
	oplus,pwm-switch-mode0-states-info = <2 1162 1>;
	oplus,pwm-switch-mode1-states-info = <2 1162 0>;
};
